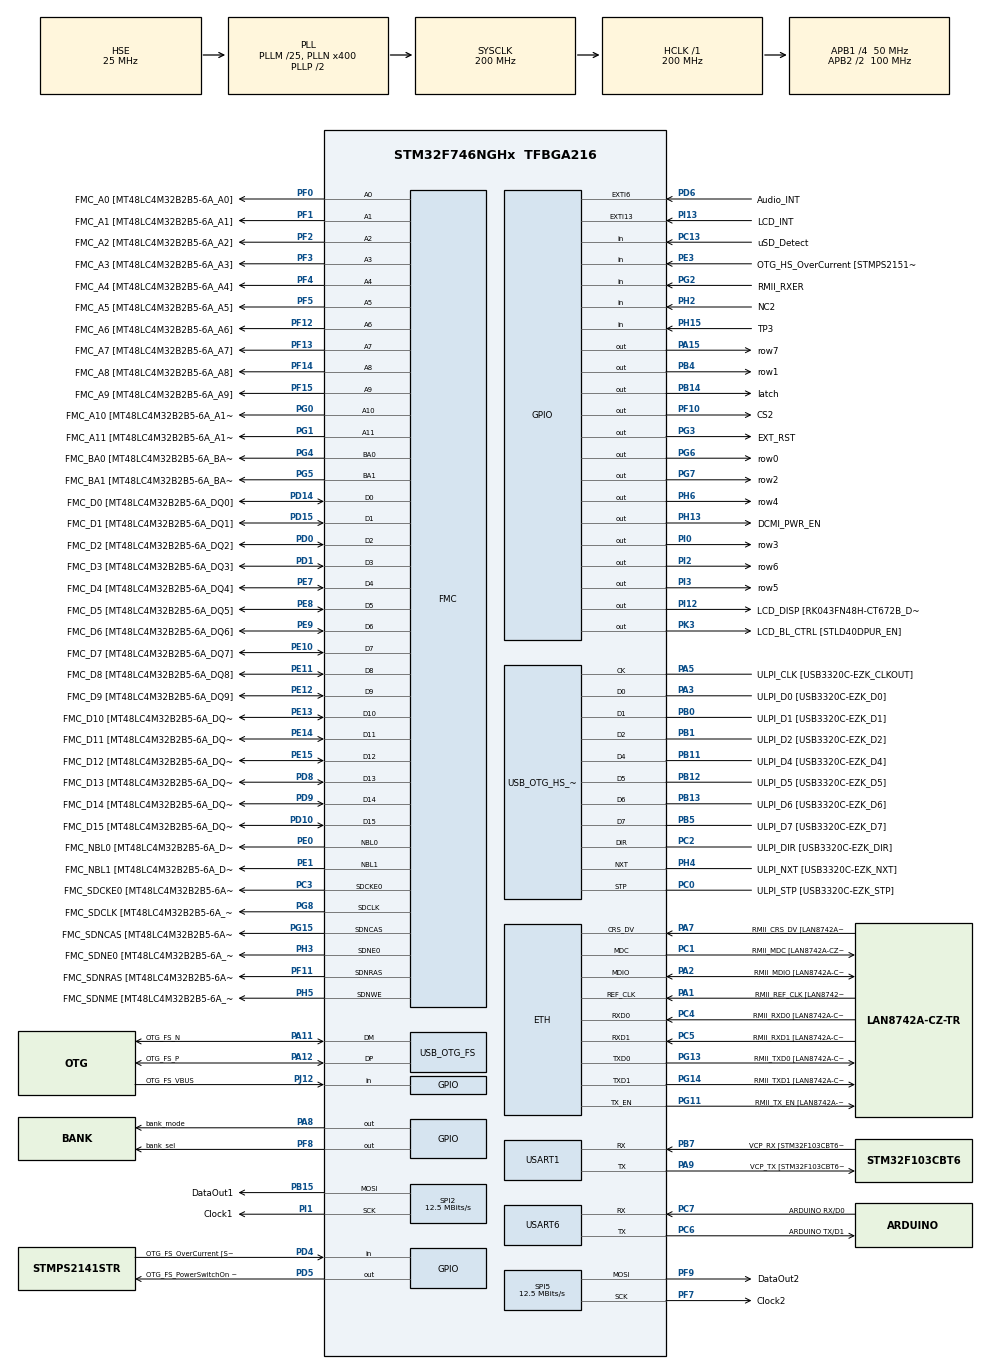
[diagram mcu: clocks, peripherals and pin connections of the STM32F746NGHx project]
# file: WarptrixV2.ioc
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Dma.MEMTOMEM.0.Direction=DMA_MEMORY_TO_MEMORY
Dma.MEMTOMEM.0.FIFOMode=DMA_FIFOMODE_ENABLE
Dma.MEMTOMEM.0.FIFOThreshold=DMA_FIFO_THRESHOLD_FULL
Dma.MEMTOMEM.0.Instance=DMA2_Stream4
Dma.MEMTOMEM.0.MemBurst=DMA_MBURST_SINGLE
Dma.MEMTOMEM.0.MemDataAlignment=DMA_MDATAALIGN_BYTE
Dma.MEMTOMEM.0.MemInc=DMA_MINC_ENABLE
Dma.MEMTOMEM.0.Mode=DMA_NORMAL
Dma.MEMTOMEM.0.PeriphBurst=DMA_PBURST_SINGLE
Dma.MEMTOMEM.0.PeriphDataAlignment=DMA_PDATAALIGN_BYTE
Dma.MEMTOMEM.0.PeriphInc=DMA_PINC_ENABLE
Dma.MEMTOMEM.0.Priority=DMA_PRIORITY_LOW
Dma.Request0=MEMTOMEM
Dma.Request1=SPI5_TX
Dma.Request2=SPI2_TX
Dma.SPI2_TX.2.Direction=DMA_MEMORY_TO_PERIPH
Dma.SPI2_TX.2.FIFOMode=DMA_FIFOMODE_DISABLE
Dma.SPI2_TX.2.Instance=DMA1_Stream4
Dma.SPI2_TX.2.MemDataAlignment=DMA_MDATAALIGN_BYTE
Dma.SPI2_TX.2.MemInc=DMA_MINC_ENABLE
Dma.SPI2_TX.2.Mode=DMA_NORMAL
Dma.SPI2_TX.2.PeriphDataAlignment=DMA_PDATAALIGN_BYTE
Dma.SPI2_TX.2.PeriphInc=DMA_PINC_DISABLE
Dma.SPI2_TX.2.Priority=DMA_PRIORITY_VERY_HIGH
Dma.SPI5_TX.1.Direction=DMA_MEMORY_TO_PERIPH
Dma.SPI5_TX.1.FIFOMode=DMA_FIFOMODE_DISABLE
Dma.SPI5_TX.1.Instance=DMA2_Stream6
Dma.SPI5_TX.1.MemDataAlignment=DMA_MDATAALIGN_BYTE
Dma.SPI5_TX.1.MemInc=DMA_MINC_ENABLE
Dma.SPI5_TX.1.Mode=DMA_NORMAL
Dma.SPI5_TX.1.PeriphDataAlignment=DMA_PDATAALIGN_BYTE
Dma.SPI5_TX.1.PeriphInc=DMA_PINC_DISABLE
Dma.SPI5_TX.1.Priority=DMA_PRIORITY_VERY_HIGH
ETH.MACAddr=00\:6D\:69\:6B\:75\:02
ETH.MediaInterface=ETH_MEDIA_INTERFACE_RMII
ETH.PHY_Name=LAN8742A_PHY_ADDRESS
ETH.PHY_RESET_DELAY=0x00000FFF
ETH.PhyAddress=0
FMC.CASLatency1=FMC_SDRAM_CAS_LATENCY_3
FMC.ExitSelfRefreshDelay1=7
FMC.LoadToActiveDelay1=2
FMC.RCDDelay1=2
FMC.RPDelay1=2
FMC.RPDelay2=2
FMC.ReadBurst1=FMC_SDRAM_RBURST_ENABLE
FMC.ReadBurst2=FMC_SDRAM_RBURST_ENABLE
FMC.RowCycleDelay1=7
FMC.RowCycleDelay2=7
FMC.SDClockPeriod1=FMC_SDRAM_CLOCK_PERIOD_2
FMC.SDClockPeriod2=FMC_SDRAM_CLOCK_PERIOD_2
FMC.SelfRefreshTime1=4
FMC.WriteRecoveryTime1=3
LWIP.LWIP_DISABLE_TCP_SANITY_CHECKS=0
LWIP.MEMP_NUM_TCP_PCB=5
LWIP.MEMP_NUM_UDP_PCB=1
LWIP.Version=v2.0.3_Cube
Mcu.Family=STM32F7
Mcu.Name=STM32F746NGHx
Mcu.Package=TFBGA216
NVIC.DMA1_Stream4_IRQn=true\:0\:0\:false\:false\:true\:false
NVIC.DMA2_Stream6_IRQn=true\:0\:0\:false\:false\:true\:false
NVIC.OTG_FS_IRQn=true\:0\:0\:false\:false\:true\:true
NVIC.PriorityGroup=NVIC_PRIORITYGROUP_4
NVIC.TIM1_BRK_TIM9_IRQn=true\:0\:0\:false\:false\:true\:true
NVIC.TIM6_DAC_IRQn=true\:0\:0\:false\:false\:true\:false
NVIC.TIM8_TRG_COM_TIM14_IRQn=true\:0\:0\:false\:false\:true\:true
NVIC.TimeBase=TIM6_DAC_IRQn
NVIC.TimeBaseIP=TIM6
PA0/WKUP.GPIO_Label=ARDUINO A0
PA0/WKUP.GPIO_Mode=GPIO_MODE_ANALOG
PA0/WKUP.GPIO_PuPd=GPIO_NOPULL
PA0/WKUP.Signal=ADCx_IN0
PA1.GPIO_Label=RMII_REF_CLK [LAN8742A-CZ-TR_REFCLK0]
PA1.Mode=RMII
PA1.Signal=ETH_REF_CLK
PA10.GPIO_Label=OTG_FS_ID
PA10.Signal=USB_OTG_FS_ID
PA11.GPIO_Label=OTG_FS_N
PA11.Mode=Device_Only
PA11.Signal=USB_OTG_FS_DM
PA12.GPIO_Label=OTG_FS_P
PA12.Mode=Device_Only
PA12.Signal=USB_OTG_FS_DP
PA13.GPIO_Label=SWDIO
PA13.Mode=Serial_Wire
PA13.Signal=SYS_JTMS-SWDIO
PA14.GPIO_Label=SWCLK
PA14.Mode=Serial_Wire
PA14.Signal=SYS_JTCK-SWCLK
PA15.GPIO_Label=row7
PA15.Signal=GPIO_Output
PA2.GPIO_Label=RMII_MDIO [LAN8742A-CZ-TR_MDIO]
PA2.Mode=RMII
PA2.Signal=ETH_MDIO
PA3.GPIO_Label=ULPI_D0 [USB3320C-EZK_D0]
PA3.Mode=Host_HS
PA3.Signal=USB_OTG_HS_ULPI_D0
PA4.GPIO_Label=DCMI_HSYNC
PA4.Signal=DCMI_HSYNC
PA5.GPIO_Label=ULPI_CLK [USB3320C-EZK_CLKOUT]
PA5.Mode=Host_HS
PA5.Signal=USB_OTG_HS_ULPI_CK
PA6.Signal=DCMI_PIXCLK
PA7.GPIO_Label=RMII_CRS_DV [LAN8742A-CZ-TR_CRS_DV]
PA7.Mode=RMII
PA7.Signal=ETH_CRS_DV
PA8.GPIO_Label=bank_mode
PA8.PinState=GPIO_PIN_SET
PA8.Signal=GPIO_Output
PA9.GPIO_Label=VCP_TX [STM32F103CBT6_PA3]
PA9.GPIO_Mode=GPIO_MODE_AF_PP
PA9.GPIO_PuPd=GPIO_NOPULL
PA9.GPIO_Speed=GPIO_SPEED_FREQ_LOW
PA9.Mode=Asynchronous
PA9.Signal=USART1_TX
PB0.GPIO_Label=ULPI_D1 [USB3320C-EZK_D1]
PB0.Mode=Host_HS
PB0.Signal=USB_OTG_HS_ULPI_D1
PB1.GPIO_Label=ULPI_D2 [USB3320C-EZK_D2]
PB1.Mode=Host_HS
PB1.Signal=USB_OTG_HS_ULPI_D2
PB10.GPIO_Label=ULPI_D3 [USB3320C-EZK_D3]
PB10.Signal=USB_OTG_HS_ULPI_D3
PB11.GPIO_Label=ULPI_D4 [USB3320C-EZK_D4]
PB11.Mode=Host_HS
PB11.Signal=USB_OTG_HS_ULPI_D4
PB12.GPIO_Label=ULPI_D5 [USB3320C-EZK_D5]
PB12.Mode=Host_HS
PB12.Signal=USB_OTG_HS_ULPI_D5
PB13.GPIO_Label=ULPI_D6 [USB3320C-EZK_D6]
PB13.Mode=Host_HS
PB13.Signal=USB_OTG_HS_ULPI_D6
PB14.GPIO_Label=latch
PB14.Signal=GPIO_Output
PB15.GPIO_Label=DataOut1
PB15.GPIO_Mode=GPIO_MODE_AF_PP
PB15.GPIO_PuPd=GPIO_NOPULL
PB15.GPIO_Speed=GPIO_SPEED_FREQ_VERY_HIGH
PB15.Mode=TX_Only_Simplex_Unidirect_Master
PB15.Signal=SPI2_MOSI
PB2.Signal=QUADSPI_CLK
PB3.GPIO_Label=SWO
PB3.Signal=SYS_JTDO-SWO
PB4.GPIO_Label=row1
PB4.Signal=GPIO_Output
PB5.GPIO_Label=ULPI_D7 [USB3320C-EZK_D7]
PB5.Mode=Host_HS
PB5.Signal=USB_OTG_HS_ULPI_D7
PB6.GPIO_Label=QSPI_NCS [N25Q128A13EF840E_S]
PB6.Signal=QUADSPI_BK1_NCS
PB7.GPIO_Label=VCP_RX [STM32F103CBT6_PA2]
PB7.GPIO_Mode=GPIO_MODE_AF_PP
PB7.GPIO_PuPd=GPIO_NOPULL
PB7.GPIO_Speed=GPIO_SPEED_FREQ_LOW
PB7.Mode=Asynchronous
PB7.Signal=USART1_RX
PB8.GPIO_Label=ARDUINO SCL/D15
PB8.GPIO_Mode=GPIO_MODE_AF_OD
PB8.GPIO_PuPd=GPIO_NOPULL
PB8.GPIO_Speed=GPIO_SPEED_FREQ_LOW
PB8.Signal=I2C1_SCL
PB9.GPIO_Label=ARDUINO SDA/D14
PB9.GPIO_Mode=GPIO_MODE_AF_OD
PB9.GPIO_PuPd=GPIO_NOPULL
PB9.GPIO_Speed=GPIO_SPEED_FREQ_LOW
PB9.Signal=I2C1_SDA
PC0.GPIO_Label=ULPI_STP [USB3320C-EZK_STP]
PC0.Mode=Host_HS
PC0.Signal=USB_OTG_HS_ULPI_STP
PC1.GPIO_Label=RMII_MDC [LAN8742A-CZ-TR_MDC]
PC1.Mode=RMII
PC1.Signal=ETH_MDC
PC10.GPIO_Label=SDMMC_D2
PC10.Signal=SDMMC1_D2
PC11.GPIO_Label=SDMMC_D3
PC11.Signal=SDMMC1_D3
PC12.GPIO_Label=SDMMC_CK
PC12.Signal=SDMMC1_CK
PC13.GPIO_Label=uSD_Detect
PC13.Signal=GPIO_Input
PC14/OSC32_IN.GPIO_Label=RCC_OSC32_IN
PC14/OSC32_IN.Mode=LSE-External-Oscillator
PC14/OSC32_IN.Signal=RCC_OSC32_IN
PC15/OSC32_OUT.GPIO_Label=RCC_OSC32_OUT
PC15/OSC32_OUT.Mode=LSE-External-Oscillator
PC15/OSC32_OUT.Signal=RCC_OSC32_OUT
PC2.GPIO_Label=ULPI_DIR [USB3320C-EZK_DIR]
PC2.Mode=Host_HS
PC2.Signal=USB_OTG_HS_ULPI_DIR
PC3.GPIO_Label=FMC_SDCKE0 [MT48LC4M32B2B5-6A_CKE]
PC3.Mode=SdramChipSelect1_1
PC3.Signal=FMC_SDCKE0
PC4.GPIO_Label=RMII_RXD0 [LAN8742A-CZ-TR_RXD0]
PC4.Mode=RMII
PC4.Signal=ETH_RXD0
PC5.GPIO_Label=RMII_RXD1 [LAN8742A-CZ-TR_RXD1]
PC5.Mode=RMII
PC5.Signal=ETH_RXD1
PC6.GPIO_Label=ARDUINO TX/D1
PC6.Mode=Asynchronous
PC6.Signal=USART6_TX
PC7.GPIO_Label=ARDUINO RX/D0
PC7.Mode=Asynchronous
PC7.Signal=USART6_RX
PC8.Signal=SDMMC1_D0
PC9.Signal=SDMMC1_D1
PD0.GPIO_Label=FMC_D2 [MT48LC4M32B2B5-6A_DQ2]
PD0.Signal=FMC_D2_DA2
PD1.GPIO_Label=FMC_D3 [MT48LC4M32B2B5-6A_DQ3]
PD1.Signal=FMC_D3_DA3
PD10.GPIO_Label=FMC_D15 [MT48LC4M32B2B5-6A_DQ15]
PD10.Signal=FMC_D15_DA15
PD11.GPIO_Label=QSPI_D0 [N25Q128A13EF840E_DQ0]
PD11.Signal=QUADSPI_BK1_IO0
PD12.GPIO_Label=QSPI_D1 [N25Q128A13EF840E_DQ1]
PD12.Signal=QUADSPI_BK1_IO1
PD13.GPIO_Label=QSPI_D3 [N25Q128A13EF840E_DQ3]
PD13.Signal=QUADSPI_BK1_IO3
PD14.GPIO_Label=FMC_D0 [MT48LC4M32B2B5-6A_DQ0]
PD14.Signal=FMC_D0_DA0
PD15.GPIO_Label=FMC_D1 [MT48LC4M32B2B5-6A_DQ1]
PD15.Signal=FMC_D1_DA1
PD2.GPIO_Label=SDMMC_CMD
PD2.Signal=SDMMC1_CMD
PD3.GPIO_Label=DCMI_D5
PD3.Signal=DCMI_D5
PD4.GPIO_Label=OTG_FS_OverCurrent [STMPS2141STR_Fault]
PD4.Signal=GPIO_Input
PD5.GPIO_Label=OTG_FS_PowerSwitchOn [STMPS2141STR_EN]
PD5.PinState=GPIO_PIN_SET
PD5.Signal=GPIO_Output
PD6.GPIO_Label=Audio_INT
PD6.GPIO_ModeDefaultEXTI=GPIO_MODE_EVT_RISING
PD6.Signal=GPXTI6
PD7.GPIO_Label=SPDIF_RX0 [74LVC1G04SE_4]
PD7.Signal=SPDIFRX_IN0
PD8.GPIO_Label=FMC_D13 [MT48LC4M32B2B5-6A_DQ13]
PD8.Signal=FMC_D13_DA13
PD9.GPIO_Label=FMC_D14 [MT48LC4M32B2B5-6A_DQ14]
PD9.Signal=FMC_D14_DA14
PE0.GPIO_Label=FMC_NBL0 [MT48LC4M32B2B5-6A_DQM0]
PE0.Signal=FMC_NBL0
PE1.GPIO_Label=FMC_NBL1 [MT48LC4M32B2B5-6A_DQM1]
PE1.Signal=FMC_NBL1
PE10.GPIO_Label=FMC_D7 [MT48LC4M32B2B5-6A_DQ7]
PE10.Signal=FMC_D7_DA7
PE11.GPIO_Label=FMC_D8 [MT48LC4M32B2B5-6A_DQ8]
PE11.Signal=FMC_D8_DA8
PE12.GPIO_Label=FMC_D9 [MT48LC4M32B2B5-6A_DQ9]
PE12.Signal=FMC_D9_DA9
PE13.GPIO_Label=FMC_D10 [MT48LC4M32B2B5-6A_DQ10]
PE13.Signal=FMC_D10_DA10
PE14.GPIO_Label=FMC_D11 [MT48LC4M32B2B5-6A_DQ11]
PE14.Signal=FMC_D11_DA11
PE15.GPIO_Label=FMC_D12 [MT48LC4M32B2B5-6A_DQ12]
PE15.Signal=FMC_D12_DA12
PE2.GPIO_Label=QSPI_D2 [N25Q128A13EF840E_DQ2]
PE2.Signal=QUADSPI_BK1_IO2
PE3.GPIO_Label=OTG_HS_OverCurrent [STMPS2151STR_FAULT]
PE3.Signal=GPIO_Input
PE4.GPIO_Label=LCD_B0 [RK043FN48H-CT672B_B0]
PE4.Signal=LTDC_B0
PE5.GPIO_Label=DCMI_D6
PE5.Signal=DCMI_D6
PE6.GPIO_Label=DCMI_D7
PE6.Signal=DCMI_D7
PE7.GPIO_Label=FMC_D4 [MT48LC4M32B2B5-6A_DQ4]
PE7.Signal=FMC_D4_DA4
PE8.GPIO_Label=FMC_D5 [MT48LC4M32B2B5-6A_DQ5]
PE8.Signal=FMC_D5_DA5
PE9.GPIO_Label=FMC_D6 [MT48LC4M32B2B5-6A_DQ6]
PE9.Signal=FMC_D6_DA6
PF0.GPIO_Label=FMC_A0 [MT48LC4M32B2B5-6A_A0]
PF0.Signal=FMC_A0
PF1.GPIO_Label=FMC_A1 [MT48LC4M32B2B5-6A_A1]
PF1.Signal=FMC_A1
PF10.GPIO_Label=CS2
PF10.Signal=GPIO_Output
PF11.GPIO_Label=FMC_SDNRAS [MT48LC4M32B2B5-6A_RAS]
PF11.Signal=FMC_SDNRAS
PF12.GPIO_Label=FMC_A6 [MT48LC4M32B2B5-6A_A6]
PF12.Signal=FMC_A6
PF13.GPIO_Label=FMC_A7 [MT48LC4M32B2B5-6A_A7]
PF13.Signal=FMC_A7
PF14.GPIO_Label=FMC_A8 [MT48LC4M32B2B5-6A_A8]
PF14.Signal=FMC_A8
PF15.GPIO_Label=FMC_A9 [MT48LC4M32B2B5-6A_A9]
PF15.Signal=FMC_A9
PF2.GPIO_Label=FMC_A2 [MT48LC4M32B2B5-6A_A2]
PF2.Signal=FMC_A2
PF3.GPIO_Label=FMC_A3 [MT48LC4M32B2B5-6A_A3]
PF3.Signal=FMC_A3
PF4.GPIO_Label=FMC_A4 [MT48LC4M32B2B5-6A_A4]
PF4.Signal=FMC_A4
PF5.GPIO_Label=FMC_A5 [MT48LC4M32B2B5-6A_A5]
PF5.Signal=FMC_A5
PF6.GPIO_Label=ARDUINO A5
PF6.GPIO_Mode=GPIO_MODE_ANALOG
PF6.GPIO_PuPd=GPIO_NOPULL
PF6.Signal=ADC3_IN4
PF7.GPIO_Label=Clock2
PF7.Mode=TX_Only_Simplex_Unidirect_Master
PF7.Signal=SPI5_SCK
PF8.GPIO_Label=bank_sel
PF8.Signal=GPIO_Output
PF9.GPIO_Label=DataOut2
PF9.Mode=TX_Only_Simplex_Unidirect_Master
PF9.Signal=SPI5_MOSI
PG0.GPIO_Label=FMC_A10 [MT48LC4M32B2B5-6A_A10]
PG0.Signal=FMC_A10
PG1.GPIO_Label=FMC_A11 [MT48LC4M32B2B5-6A_A11]
PG1.Signal=FMC_A11
PG10.GPIO_Label=SAI2_SDB [WM8994ECS/R_ADCDAT1]
PG10.Signal=SAI2_SD_B
PG11.GPIO_Label=RMII_TX_EN [LAN8742A-CZ-TR_TXEN]
PG11.Mode=RMII
PG11.Signal=ETH_TX_EN
PG12.GPIO_Label=LCD_B4 [RK043FN48H-CT672B_B4]
PG12.Signal=LTDC_B4
PG13.GPIO_Label=RMII_TXD0 [LAN8742A-CZ-TR_TXD0]
PG13.Mode=RMII
PG13.Signal=ETH_TXD0
PG14.GPIO_Label=RMII_TXD1 [LAN8742A-CZ-TR_TXD1]
PG14.Mode=RMII
PG14.Signal=ETH_TXD1
PG15.GPIO_Label=FMC_SDNCAS [MT48LC4M32B2B5-6A_CAS]
PG15.Signal=FMC_SDNCAS
PG2.GPIO_Label=RMII_RXER
PG2.Signal=GPIO_Input
PG3.GPIO_Label=EXT_RST
PG3.Signal=GPIO_Output
PG4.GPIO_Label=FMC_BA0 [MT48LC4M32B2B5-6A_BA0]
PG4.Signal=FMC_A14_BA0
PG5.GPIO_Label=FMC_BA1 [MT48LC4M32B2B5-6A_BA1]
PG5.Signal=FMC_A15_BA1
PG6.GPIO_Label=row0
PG6.Signal=GPIO_Output
PG7.GPIO_Label=row2
PG7.Signal=GPIO_Output
PG8.GPIO_Label=FMC_SDCLK [MT48LC4M32B2B5-6A_CLK]
PG8.Signal=FMC_SDCLK
PG9.GPIO_Label=DCMI_VSYNC
PG9.Signal=DCMI_VSYNC
PH0/OSC_IN.GPIO_Label=OSC_25M [NZ2520SB-25.00M_OUT]
PH0/OSC_IN.Mode=HSE-External-Oscillator
PH0/OSC_IN.Signal=RCC_OSC_IN
PH1/OSC_OUT.Mode=HSE-External-Oscillator
PH1/OSC_OUT.Signal=RCC_OSC_OUT
PH10.GPIO_Label=DCMI_D1
PH10.Signal=DCMI_D1
PH11.GPIO_Label=DCMI_D2
PH11.Signal=DCMI_D2
PH12.GPIO_Label=DCMI_D3
PH12.Signal=DCMI_D3
PH13.GPIO_Label=DCMI_PWR_EN
PH13.Signal=GPIO_Output
PH14.GPIO_Label=DCMI_D4
PH14.Signal=DCMI_D4
PH15.GPIO_Label=TP3
PH15.Signal=GPIO_Input
PH2.GPIO_Label=NC2
PH2.Signal=GPIO_Input
PH3.GPIO_Label=FMC_SDNE0 [MT48LC4M32B2B5-6A_CS]
PH3.Mode=SdramChipSelect1_1
PH3.Signal=FMC_SDNE0
PH4.GPIO_Label=ULPI_NXT [USB3320C-EZK_NXT]
PH4.Mode=Host_HS
PH4.Signal=USB_OTG_HS_ULPI_NXT
PH5.GPIO_Label=FMC_SDNME [MT48LC4M32B2B5-6A_WE]
PH5.Signal=FMC_SDNWE
PH6.GPIO_Label=row4
PH6.Signal=GPIO_Output
PH7.GPIO_Label=LCD_SCL [RK043FN48H-CT672B_SCL]
PH7.Signal=I2C3_SCL
PH8.GPIO_Label=LCD_SDA [RK043FN48H-CT672B_SDA]
PH8.Signal=I2C3_SDA
PH9.GPIO_Label=DCMI_D0
PH9.Signal=DCMI_D0
PI0.GPIO_Label=row3
PI0.Signal=GPIO_Output
PI1.GPIO_Label=Clock1
PI1.GPIO_Mode=GPIO_MODE_AF_PP
PI1.GPIO_PuPd=GPIO_NOPULL
PI1.GPIO_Speed=GPIO_SPEED_FREQ_VERY_HIGH
PI1.Mode=TX_Only_Simplex_Unidirect_Master
PI1.Signal=SPI2_SCK
PI10.GPIO_Label=LCD_HSYNC [RK043FN48H-CT672B_HSYNC]
PI10.Signal=LTDC_HSYNC
PI12.GPIO_Label=LCD_DISP [RK043FN48H-CT672B_DISP] 
PI12.PinState=GPIO_PIN_SET
PI12.Signal=GPIO_Output
PI13.GPIO_Label=LCD_INT
PI13.GPIO_ModeDefaultEXTI=GPIO_MODE_EVT_RISING
PI13.Signal=GPXTI13
PI14.GPIO_Label=LCD_CLK [RK043FN48H-CT672B_CLK]
PI14.Signal=LTDC_CLK
PI15.GPIO_Label=LCD_R0 [RK043FN48H-CT672B_R0]
PI15.Signal=LTDC_R0
PI2.GPIO_Label=row6
PI2.Signal=GPIO_Output
PI3.GPIO_Label=row5
PI3.Signal=GPIO_Output
PI4.GPIO_Label=SAI2_MCLKA [WM8994ECS/R_MCLK1]
PI4.Signal=SAI2_MCLK_A
PI5.GPIO_Label=SAI2_SCKA [WM8994ECS/R_BCLK1]
PI5.Signal=SAI2_SCK_A
PI6.GPIO_Label=SAI2_SDA [WM8994ECS/R_DACDAT1]
PI6.Signal=SAI2_SD_A
PI7.GPIO_Label=SAI2_FSA [WM8994ECS/R_LRCLK1]
PI7.Signal=SAI2_FS_A
PI8.GPIO_Label=NC1 [TP2]
PI8.Signal=RTC_TS
PI9.GPIO_Label=LCD_VSYNC [RK043FN48H-CT672B_VSYNC]
PI9.Signal=LTDC_VSYNC
PJ0.GPIO_Label=LCD_R1 [RK043FN48H-CT672B_R1]
PJ0.Signal=LTDC_R1
PJ1.GPIO_Label=LCD_R2 [RK043FN48H-CT672B_R2]
PJ1.Signal=LTDC_R2
PJ10.GPIO_Label=LCD_G3 [RK043FN48H-CT672B_G3]
PJ10.Signal=LTDC_G3
PJ11.GPIO_Label=LCD_G4 [RK043FN48H-CT672B_G4]
PJ11.Signal=LTDC_G4
PJ12.GPIO_Label=OTG_FS_VBUS
PJ12.Signal=GPIO_Input
PJ13.GPIO_Label=LCD_B1 [RK043FN48H-CT672B_B1]
PJ13.Signal=LTDC_B1
PJ14.GPIO_Label=LCD_B2 [RK043FN48H-CT672B_B2]
PJ14.Signal=LTDC_B2
PJ15.GPIO_Label=LCD_B3 [RK043FN48H-CT672B_B3]
PJ15.Signal=LTDC_B3
PJ2.GPIO_Label=LCD_R3 [RK043FN48H-CT672B_R3]
PJ2.Signal=LTDC_R3
PJ3.GPIO_Label=LCD_R4 [RK043FN48H-CT672B_R4]
PJ3.Signal=LTDC_R4
PJ4.GPIO_Label=LCD_R5 [RK043FN48H-CT672B_R5]
PJ4.Signal=LTDC_R5
PJ5.GPIO_Label=LCD_R6 [RK043FN48H-CT672B_R6]
PJ5.Signal=LTDC_R6
PJ6.GPIO_Label=LCD_R7 [RK043FN48H-CT672B_R7]
PJ6.Signal=LTDC_R7
PJ7.GPIO_Label=LCD_G0 [RK043FN48H-CT672B_G0]
PJ7.Signal=LTDC_G0
PJ8.GPIO_Label=LCD_G1 [RK043FN48H-CT672B_G1]
PJ8.Signal=LTDC_G1
PJ9.GPIO_Label=LCD_G2 [RK043FN48H-CT672B_G2]
PJ9.Signal=LTDC_G2
PK0.GPIO_Label=LCD_G5 [RK043FN48H-CT672B_G5]
PK0.Signal=LTDC_G5
PK1.GPIO_Label=LCD_G6 [RK043FN48H-CT672B_G6]
PK1.Signal=LTDC_G6
PK2.GPIO_Label=LCD_G7 [RK043FN48H-CT672B_G7]
PK2.Signal=LTDC_G7
PK3.GPIO_Label=LCD_BL_CTRL [STLD40DPUR_EN]
PK3.GPIO_Speed=GPIO_SPEED_FREQ_LOW
PK3.PinState=GPIO_PIN_SET
PK3.Signal=GPIO_Output
PK4.GPIO_Label=LCD_B5 [RK043FN48H-CT672B_B5]
PK4.Signal=LTDC_B5
PK5.GPIO_Label=LCD_B6 [RK043FN48H-CT672B_B6]
PK5.Signal=LTDC_B6
PK6.GPIO_Label=LCD_B7 [RK043FN48H-CT672B_B7]
PK6.Signal=LTDC_B7
PK7.GPIO_Label=LCD_DE [RK043FN48H-CT672B_DE]
PK7.Signal=LTDC_DE
ProjectManager.HeapSize=0x200
ProjectManager.StackSize=0x400
ProjectManager.TargetToolchain=Makefile
RCC.AHBFreq_Value=200000000
RCC.APB1CLKDivider=RCC_HCLK_DIV4
RCC.APB1Freq_Value=50000000
RCC.APB1TimFreq_Value=100000000
RCC.APB2CLKDivider=RCC_HCLK_DIV2
RCC.APB2Freq_Value=100000000
RCC.APB2TimFreq_Value=200000000
RCC.CortexFreq_Value=200000000
RCC.HCLKFreq_Value=200000000
RCC.HSE_VALUE=25000000
RCC.HSI_VALUE=16000000
RCC.PLL48CLockSelection=RCC_CLK48SOURCE_PLLSAIP
RCC.PLLI2SN=100
RCC.PLLM=25
RCC.PLLN=400
RCC.PLLQ=9
RCC.PLLSAIN=384
RCC.PLLSAIP=RCC_PLLSAIP_DIV8
RCC.PLLSAIR=5
RCC.PLLSAIRDiv=RCC_PLLSAIDIVR_8
RCC.SDMMCClockSelection=RCC_SDMMC1CLKSOURCE_CLK48
RCC.SYSCLKFreq_VALUE=200000000
RCC.SYSCLKSource=RCC_SYSCLKSOURCE_PLLCLK
RCC.USBFreq_Value=48000000
RCC.VCOOutputFreq_Value=400000000
SH.ADCx_IN0.0=ADC3_IN0
SH.FMC_A0.0=FMC_A0,12b-sda1
SH.FMC_A1.0=FMC_A1,12b-sda1
SH.FMC_A10.0=FMC_A10,12b-sda1
SH.FMC_A11.0=FMC_A11,12b-sda1
SH.FMC_A14_BA0.0=FMC_BA0,FourSdramBanks1
SH.FMC_A15_BA1.0=FMC_BA1,FourSdramBanks1
SH.FMC_A2.0=FMC_A2,12b-sda1
SH.FMC_A3.0=FMC_A3,12b-sda1
SH.FMC_A4.0=FMC_A4,12b-sda1
SH.FMC_A5.0=FMC_A5,12b-sda1
SH.FMC_A6.0=FMC_A6,12b-sda1
SH.FMC_A7.0=FMC_A7,12b-sda1
SH.FMC_A8.0=FMC_A8,12b-sda1
SH.FMC_A9.0=FMC_A9,12b-sda1
SH.FMC_D0_DA0.0=FMC_D0,sd-16b-d1
SH.FMC_D10_DA10.0=FMC_D10,sd-16b-d1
SH.FMC_D11_DA11.0=FMC_D11,sd-16b-d1
SH.FMC_D12_DA12.0=FMC_D12,sd-16b-d1
SH.FMC_D13_DA13.0=FMC_D13,sd-16b-d1
SH.FMC_D14_DA14.0=FMC_D14,sd-16b-d1
SH.FMC_D15_DA15.0=FMC_D15,sd-16b-d1
SH.FMC_D1_DA1.0=FMC_D1,sd-16b-d1
SH.FMC_D2_DA2.0=FMC_D2,sd-16b-d1
SH.FMC_D3_DA3.0=FMC_D3,sd-16b-d1
SH.FMC_D4_DA4.0=FMC_D4,sd-16b-d1
SH.FMC_D5_DA5.0=FMC_D5,sd-16b-d1
SH.FMC_D6_DA6.0=FMC_D6,sd-16b-d1
SH.FMC_D7_DA7.0=FMC_D7,sd-16b-d1
SH.FMC_D8_DA8.0=FMC_D8,sd-16b-d1
SH.FMC_D9_DA9.0=FMC_D9,sd-16b-d1
SH.FMC_NBL0.0=FMC_NBL0,Sd2ByteEnable1
SH.FMC_NBL1.0=FMC_NBL1,Sd2ByteEnable1
SH.FMC_SDCLK.0=FMC_SDCLK,12b-sda1
SH.FMC_SDNCAS.0=FMC_SDNCAS,12b-sda1
SH.FMC_SDNRAS.0=FMC_SDNRAS,12b-sda1
SH.FMC_SDNWE.0=FMC_SDNWE,12b-sda1
SPI2.BaudRatePrescaler=SPI_BAUDRATEPRESCALER_4
SPI2.CLKPhase=SPI_PHASE_2EDGE
SPI2.CalculateBaudRate=12.5 MBits/s
SPI2.DataSize=SPI_DATASIZE_8BIT
SPI2.Direction=SPI_DIRECTION_2LINES
SPI2.FirstBit=SPI_FIRSTBIT_LSB
SPI2.Mode=SPI_MODE_MASTER
SPI2.VirtualType=VM_MASTER
SPI5.BaudRatePrescaler=SPI_BAUDRATEPRESCALER_8
SPI5.CLKPhase=SPI_PHASE_2EDGE
SPI5.CLKPolarity=SPI_POLARITY_HIGH
SPI5.CalculateBaudRate=12.5 MBits/s
SPI5.DataSize=SPI_DATASIZE_8BIT
SPI5.Direction=SPI_DIRECTION_2LINES
SPI5.FirstBit=SPI_FIRSTBIT_LSB
SPI5.Mode=SPI_MODE_MASTER
SPI5.VirtualType=VM_MASTER
TIM9.Period=5000
TIM9.Prescaler=2
USART1.VirtualMode-Asynchronous=VM_ASYNC
USART6.VirtualMode-Asynchronous=VM_ASYNC
USB_DEVICE.CLASS_NAME_FS=CDC
USB_DEVICE.LANGID_STRING-CDC_FS=1031
USB_DEVICE.MANUFACTURER_STRING-CDC_FS=Warpzone
USB_DEVICE.PID_CDC_FS=14649
USB_DEVICE.USBD_DEBUG_LEVEL-CDC_FS=2
USB_DEVICE.USBD_SELF_POWERED-CDC_FS=1
USB_DEVICE.VID-CDC_FS=4919
USB_DEVICE.VirtualMode-CDC_FS=Cdc
USB_DEVICE.VirtualModeFS=Cdc_FS
USB_OTG_FS.VirtualMode=Device_Only
VP_CRC_VS_CRC.Mode=CRC_Activate
VP_LWIP_VS_Enabled.Mode=Enabled
VP_SYS_VS_tim6.Mode=TIM6
VP_TIM1_VS_ClockSourceINT.Mode=Internal
VP_TIM2_VS_ClockSourceINT.Mode=Internal
VP_TIM3_VS_ClockSourceINT.Mode=Internal
VP_TIM5_VS_ClockSourceINT.Mode=Internal
VP_TIM8_VS_ClockSourceINT.Mode=Internal
VP_TIM9_VS_ClockSourceINT.Mode=Internal
VP_USB_DEVICE_VS_USB_DEVICE_CDC_FS.Mode=CDC_FS
board=32F746GDISCOVERY

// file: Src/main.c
/**
  ******************************************************************************
  * @file           : main.c
  * @brief          : Main program body
  ******************************************************************************
  * This notice applies to any and all portions of this file
  * that are not between comment pairs USER CODE BEGIN and
  * USER CODE END. Other portions of this file, whether
  * inserted by the user or by software development tools
  * are owned by their respective copyright owners.
  *
  * Copyright (c) 2019 STMicroelectronics International N.V.
  * All rights reserved.
  *
  * Redistribution and use in source and binary forms, with or without
  * modification, are permitted, provided that the following conditions are met:
  *
  * 1. Redistribution of source code must retain the above copyright notice,
  *    this list of conditions and the following disclaimer.
  * 2. Redistributions in binary form must reproduce the above copyright notice,
  *    this list of conditions and the following disclaimer in the documentation
  *    and/or other materials provided with the distribution.
  * 3. Neither the name of STMicroelectronics nor the names of other
  *    contributors to this software may be used to endorse or promote products
  *    derived from this software without specific written permission.
  * 4. This software, including modifications and/or derivative works of this
  *    software, must execute solely and exclusively on microcontroller or
  *    microprocessor devices manufactured by or for STMicroelectronics.
  * 5. Redistribution and use of this software other than as permitted under
  *    this license is void and will automatically terminate your rights under
  *    this license.
  *
  * THIS SOFTWARE IS PROVIDED BY STMICROELECTRONICS AND CONTRIBUTORS "AS IS"
  * AND ANY EXPRESS, IMPLIED OR STATUTORY WARRANTIES, INCLUDING, BUT NOT
  * LIMITED TO, THE IMPLIED WARRANTIES OF MERCHANTABILITY, FITNESS FOR A
  * PARTICULAR PURPOSE AND NON-INFRINGEMENT OF THIRD PARTY INTELLECTUAL PROPERTY
  * RIGHTS ARE DISCLAIMED TO THE FULLEST EXTENT PERMITTED BY LAW. IN NO EVENT
  * SHALL STMICROELECTRONICS OR CONTRIBUTORS BE LIABLE FOR ANY DIRECT, INDIRECT,
  * INCIDENTAL, SPECIAL, EXEMPLARY, OR CONSEQUENTIAL DAMAGES (INCLUDING, BUT NOT
  * LIMITED TO, PROCUREMENT OF SUBSTITUTE GOODS OR SERVICES; LOSS OF USE, DATA,
  * OR PROFITS; OR BUSINESS INTERRUPTION) HOWEVER CAUSED AND ON ANY THEORY OF
  * LIABILITY, WHETHER IN CONTRACT, STRICT LIABILITY, OR TORT (INCLUDING
  * NEGLIGENCE OR OTHERWISE) ARISING IN ANY WAY OUT OF THE USE OF THIS SOFTWARE,
  * EVEN IF ADVISED OF THE POSSIBILITY OF SUCH DAMAGE.
  *
  ******************************************************************************
  */
#include "main.h"
#include "stm32f7xx_hal.h"
#include "lwip.h"
#include "usb_device.h"

/* USER CODE BEGIN Includes */
#include "usbd_cdc_if.h"
#include "tcp.h"

/* USER CODE END Includes */

CRC_HandleTypeDef hcrc;

SPI_HandleTypeDef hspi2;
SPI_HandleTypeDef hspi5;
DMA_HandleTypeDef hdma_spi2_tx;
DMA_HandleTypeDef hdma_spi5_tx;

TIM_HandleTypeDef htim1;
TIM_HandleTypeDef htim2;
TIM_HandleTypeDef htim3;
TIM_HandleTypeDef htim5;
TIM_HandleTypeDef htim8;
TIM_HandleTypeDef htim9;

UART_HandleTypeDef huart1;
UART_HandleTypeDef huart6;

DMA_HandleTypeDef hdma_memtomem_dma2_stream4;
SDRAM_HandleTypeDef hsdram1;

/* USER CODE BEGIN PV */
/* Private variables ---------------------------------------------------------*/

#define PORT_TCP_RECEIVE 1236
#define TCP_CONNECTION_TIMEOUT 10

#define USB_MAP_DEBUGG 0
#define USB_SPI_DEBUGG 0
#define USB_TCP_DEBUGG 0
#define USB_TIM_DEBUGG 0
#define USB_NET_STATUS 0
#define USB_PBUF_DEBUGG 0
#define USB_WELCOME_MSG 0

#define VERSION_STRING "V0.1"
#define WELCOME_MSG "\r\n\r\nWarptrix LED-Panel on duty! \r\nWarptrix COMPORT debugg interface. \r\nVersion: '%s' \r\n\r\n"

#define SHIFTREGS_PER_PANEL 6 // Number of 8-bit shift registers per panel. Each register controlls 8 colums of the matrix
#define ROWS 8 // Number of row drivers. 1:8 row plexed matrix
#define X_PANEL_NR 10 // Nubmer of panels in X
#define Y_PANEL_NR 4 // Number of panels in Y.
#define SHIFTREGS (X_PANEL_NR*Y_PANEL_NR*SHIFTREGS_PER_PANEL) // Total number of registers (240 with 4 panels in Y, 120 with 2 in Y)
#define LATCH_DELAY 40 // number of NOPs to wait after the data is latched. Prevents ghosting between frames.
#define X_SIZE (X_PANEL_NR * SHIFTREGS_PER_PANEL * 4 / 3) //Number of registers (bytes) in X-direction 80.
#define Y_SIZE (Y_PANEL_NR * ROWS * 3)                //Number of LED rows, NOT bytes! 96
#define COLUMS (SHIFTREGS * 4) // 960
#define COLUMS_PER_PANEL (SHIFTREGS_PER_PANEL * 4)  // 24
#define SUBFRAMES 16// Max Number of Subframes. 4-bit SoftPWM for each LED

// State-machiene defines
#define STATE_NONE 0
// start command
#define STATE_S 1
#define STATE_ST 2
#define STATE_STA 3
#define STATE_STAR 4
#define STATE_START 5
#define STATE_HIGHBYTE 6
#define STATE_LOWBYTE 7
// mode command
#define STATE_M 10
#define STATE_MO 11
#define STATE_MOD 12
#define STATE_MODE 13
#define STATE_MODE_1 14
#define STATE_MODE_2 15
#define STATE_MODE_3 16
#define STATE_MODE_4 17
#define STATE_MODE_5 18
#define STATE_MODE_6 19

// dma commands
#define STATE_D 20
#define STATE_DM 21
#define STATE_DMA 22

#define NEXT 255
#define GET_FRAME 254
#define GET_RAW_FRAME 253 // deprecated

// One frame consists of up to 16 subframes to imitate a simple software PWM.
// Each LED has 4-bit brightness. One byte in an incoming frames consists of two half-bytes, describing to 2 LEDs.
// The high half (high nibble) is for the left, low half (low nibble) for the right LED.

// one panel consists of 6 shift registers (6 bytes), format: 16*24 leds
/*
*        1       2
*   1 oooooooo oooooooo
*   2 oooooooo oooooooo
*   3 oooooooo oooooooo
*   4 oooooooo oooooooo
*   5 oooooooo oooooooo
*   6 oooooooo oooooooo
*   7 oooooooo oooooooo
*   8 oooooooo oooooooo
*        3       4
*   1 oooooooo oooooooo
*   2 oooooooo oooooooo
*   3 oooooooo oooooooo
*   4 oooooooo oooooooo
*   5 oooooooo oooooooo
*   6 oooooooo oooooooo
*   7 oooooooo oooooooo
*   8 oooooooo oooooooo
*        5       6
*   1 oooooooo oooooooo
*   2 oooooooo oooooooo
*   3 oooooooo oooooooo
*   4 oooooooo oooooooo
*   5 oooooooo oooooooo
*   6 oooooooo oooooooo
*   7 oooooooo oooooooo
*   8 oooooooo oooooooo
*/

extern struct netif gnetif;
struct tcp_pcb *pcb_tcp;

struct ip_struct {
    uint32_t ip_hex;
    uint8_t a;
    uint8_t b;
    uint8_t c;
    uint8_t d;
};

struct ip_struct my_ip;

char usb_data_out[2000];
//char usb_data_in[100];
char tcp1_status[100];
char tcp2_status[100];
char tcp3_status[100];
//char tcp4_status[400];
//char tcp5_status[400];
//char tcp6_status[400];
uint32_t status_counter = 0;
volatile uint32_t tcp_connection_timeout_counter = 0;

uint32_t current_position = 0; // deprecated?
uint32_t receiving_frame = 0;
uint32_t new_input_frame = 1;
volatile uint32_t new_output_frame = 1;
uint32_t processing_frame = 0;
volatile uint32_t next_frame = 1;
volatile uint32_t dma_swiched = 0;
uint32_t t_fps = 0;
uint32_t t_rps = 0;
uint32_t fps = 0;
uint32_t rps = 0;

uint32_t len = 0;
uint8_t *data;
uint32_t pos = 0;
uint8_t tcp_state = STATE_NONE;
uint8_t tcp_recv_state = NEXT;
uint32_t frame_len = 0;
uint32_t bytes_to_copy = 0;
uint32_t bytes_copied = 0;

uint8_t currentRow = 0;
uint8_t currentPanelRow = 0;
uint8_t currentSubframe = 0;
uint8_t inputBuffer[Y_SIZE*X_SIZE] = {0};
uint8_t frameBuffer[ROWS][COLUMS] = {0};
uint8_t outputBuffer_0[SUBFRAMES*ROWS*SHIFTREGS] = {0};
uint8_t outputBuffer_1[SUBFRAMES*ROWS*SHIFTREGS] = {0};
uint8_t current_buffer = 0; // buffer currently read from
uint8_t use_both_panels = 1; // use one or two panels. using one panel is twice as fast
uint8_t stop_dmas = 1;
uint8_t dma_spi_done = 1;
uint32_t dma_timeout = 0;
volatile uint32_t tim9_counter = 0;
HAL_StatusTypeDef spi2_err = HAL_OK;
HAL_StatusTypeDef spi5_err = HAL_OK;
HAL_StatusTypeDef spi2_error = HAL_OK; // used as flagg for debugging
HAL_StatusTypeDef spi5_error = HAL_OK;

uint8_t startup_pattern = 0;
uint8_t use_subframe_nr = SUBFRAMES;
uint8_t max_fps = 30;
volatile uint32_t milli_counter = 0;
volatile uint32_t milli_max = 0;

/* USER CODE END PV */

void SystemClock_Config(void);
static void MX_GPIO_Init(void);
static void MX_DMA_Init(void);
static void MX_CRC_Init(void);
static void MX_SPI2_Init(void);
static void MX_TIM1_Init(void);
static void MX_TIM2_Init(void);
static void MX_TIM3_Init(void);
static void MX_TIM5_Init(void);
static void MX_TIM8_Init(void);
static void MX_USART1_UART_Init(void);
static void MX_USART6_UART_Init(void);
static void MX_SPI5_Init(void);
static void MX_FMC_Init(void);
static void MX_TIM9_Init(void);

/* USER CODE BEGIN PFP */
/* Private function prototypes -----------------------------------------------*/

static void tcp_setup(void);
static err_t tcp_connection_accepted(void *arg, struct tcp_pcb *newpcb, err_t err);
static err_t tcp_receive_callback(void *arg, struct tcp_pcb *tpcb, struct pbuf *p, err_t err);
static void close_connection(struct tcp_pcb *pcb, char *reason);
static err_t tcp_poll_timeout(void *args,struct tcp_pcb *tpcb);
static uint8_t tcp_StateMachiene(char d);

static void map_inputBuffer_to_frameBuffer();
static void map_frameBuffer_to_outputBuffer(void);
static void test_Pattern_inputBuffer(void);
static void test_Pattern_frameBuffer(void);
static void test_Pattern_outputBuffer(void);
static void reset(void);
static void send_status(void);
static void update_fps(void);
static void update_rps(void);
static void stop_display(void);
static void start_display(void);

void HAL_SPI_TxCpltCallback(SPI_HandleTypeDef * spi);

/* USER CODE END PFP */

int main(void)
{

  /* MCU Configuration----------------------------------------------------------*/

  /* Reset of all peripherals, Initializes the Flash interface and the Systick. */
  HAL_Init();

  /* Configure the system clock */
  SystemClock_Config();

  /* Initialize all configured peripherals */
  MX_GPIO_Init();
  MX_DMA_Init();
  MX_CRC_Init();
  MX_SPI2_Init();
  MX_TIM1_Init();
  MX_TIM2_Init();
  MX_TIM3_Init();
  MX_TIM5_Init();
  MX_TIM8_Init();
  MX_USART1_UART_Init();
  MX_USART6_UART_Init();
  MX_SPI5_Init();
  MX_LWIP_Init();
  MX_USB_DEVICE_Init();
  MX_FMC_Init();
  MX_TIM9_Init();
  /* USER CODE BEGIN 2 */

  HAL_TIM_Base_Start_IT(&htim9);
  stop_display();
  HAL_Delay(2000);
  my_ip.ip_hex = netif_ip4_addr(&gnetif)->addr;
  my_ip.d = (my_ip.ip_hex & 0xff000000) >> 24;
  my_ip.c = (my_ip.ip_hex & 0x00ff0000) >> 16;
  my_ip.b = (my_ip.ip_hex & 0x0000ff00) >> 8;
  my_ip.a = (my_ip.ip_hex & 0x000000ff) >> 0;
  if(USB_WELCOME_MSG) memset(usb_data_out, 0, sizeof(usb_data_out));
  if(USB_WELCOME_MSG) sprintf(usb_data_out,WELCOME_MSG,my_ip.a,my_ip.b,my_ip.c,my_ip.d,VERSION_STRING);
  if(USB_WELCOME_MSG) usb_send_data(usb_data_out,sizeof(usb_data_out),10000);
  milli_max = (uint32_t) 1000.0/max_fps;
  MX_LWIP_Process();
  tcp_setup();
  reset();
  start_display();

  /* USER CODE END 2 */

  /* Infinite loop */
  /* USER CODE BEGIN WHILE */
    while (1) {
    MX_LWIP_Process();
    status_counter++;
    dma_timeout++;
    if(status_counter == 5000000){ send_status(); status_counter = 0;}
    if(spi2_error != HAL_OK || spi5_error != HAL_OK){
        if(USB_SPI_DEBUGG) memset(usb_data_out, 0, sizeof(usb_data_out));
        if(USB_SPI_DEBUGG) sprintf(usb_data_out,"ERROR IN SPI_DMA ROUTINE: \r\nspi2: %d\r\nspi5: %d\r\n",spi2_error,spi5_error);
        if(USB_SPI_DEBUGG) usb_send_data(usb_data_out,sizeof(usb_data_out),10000);
        spi2_error = HAL_OK;
        spi5_error = HAL_OK;
    }
  /* USER CODE END WHILE */

  }

}

void SystemClock_Config(void)
{

  RCC_OscInitTypeDef RCC_OscInitStruct;
  RCC_ClkInitTypeDef RCC_ClkInitStruct;
  RCC_PeriphCLKInitTypeDef PeriphClkInitStruct;

    /**Configure the main internal regulator output voltage
    */
  __HAL_RCC_PWR_CLK_ENABLE();

  __HAL_PWR_VOLTAGESCALING_CONFIG(PWR_REGULATOR_VOLTAGE_SCALE1);

    /**Initializes the CPU, AHB and APB busses clocks
    */
  RCC_OscInitStruct.OscillatorType = RCC_OSCILLATORTYPE_HSE;
  RCC_OscInitStruct.HSEState = RCC_HSE_ON;
  RCC_OscInitStruct.PLL.PLLState = RCC_PLL_ON;
  RCC_OscInitStruct.PLL.PLLSource = RCC_PLLSOURCE_HSE;
  RCC_OscInitStruct.PLL.PLLM = 25;
  RCC_OscInitStruct.PLL.PLLN = 400;
  RCC_OscInitStruct.PLL.PLLP = RCC_PLLP_DIV2;
  RCC_OscInitStruct.PLL.PLLQ = 9;
  if (HAL_RCC_OscConfig(&RCC_OscInitStruct) != HAL_OK)
  {
    _Error_Handler(__FILE__, __LINE__);
  }

    /**Activate the Over-Drive mode
    */
  if (HAL_PWREx_EnableOverDrive() != HAL_OK)
  {
    _Error_Handler(__FILE__, __LINE__);
  }

    /**Initializes the CPU, AHB and APB busses clocks
    */
  RCC_ClkInitStruct.ClockType = RCC_CLOCKTYPE_HCLK|RCC_CLOCKTYPE_SYSCLK
                              |RCC_CLOCKTYPE_PCLK1|RCC_CLOCKTYPE_PCLK2;
  RCC_ClkInitStruct.SYSCLKSource = RCC_SYSCLKSOURCE_PLLCLK;
  RCC_ClkInitStruct.AHBCLKDivider = RCC_SYSCLK_DIV1;
  RCC_ClkInitStruct.APB1CLKDivider = RCC_HCLK_DIV4;
  RCC_ClkInitStruct.APB2CLKDivider = RCC_HCLK_DIV2;

  if (HAL_RCC_ClockConfig(&RCC_ClkInitStruct, FLASH_LATENCY_6) != HAL_OK)
  {
    _Error_Handler(__FILE__, __LINE__);
  }

  PeriphClkInitStruct.PeriphClockSelection = RCC_PERIPHCLK_USART1|RCC_PERIPHCLK_USART6
                              |RCC_PERIPHCLK_CLK48;
  PeriphClkInitStruct.PLLSAI.PLLSAIN = 384;
  PeriphClkInitStruct.PLLSAI.PLLSAIR = 5;
  PeriphClkInitStruct.PLLSAI.PLLSAIQ = 2;
  PeriphClkInitStruct.PLLSAI.PLLSAIP = RCC_PLLSAIP_DIV8;
  PeriphClkInitStruct.PLLSAIDivQ = 1;
  PeriphClkInitStruct.PLLSAIDivR = RCC_PLLSAIDIVR_8;
  PeriphClkInitStruct.Usart1ClockSelection = RCC_USART1CLKSOURCE_PCLK2;
  PeriphClkInitStruct.Usart6ClockSelection = RCC_USART6CLKSOURCE_PCLK2;
  PeriphClkInitStruct.Clk48ClockSelection = RCC_CLK48SOURCE_PLLSAIP;
  if (HAL_RCCEx_PeriphCLKConfig(&PeriphClkInitStruct) != HAL_OK)
  {
    _Error_Handler(__FILE__, __LINE__);
  }

    /**Configure the Systick interrupt time
    */
  HAL_SYSTICK_Config(HAL_RCC_GetHCLKFreq()/1000);

    /**Configure the Systick
    */
  HAL_SYSTICK_CLKSourceConfig(SYSTICK_CLKSOURCE_HCLK);

  /* SysTick_IRQn interrupt configuration */
  HAL_NVIC_SetPriority(SysTick_IRQn, 0, 0);
}

/* CRC init function */
static void MX_CRC_Init(void)
{

  hcrc.Instance = CRC;
  hcrc.Init.DefaultPolynomialUse = DEFAULT_POLYNOMIAL_ENABLE;
  hcrc.Init.DefaultInitValueUse = DEFAULT_INIT_VALUE_ENABLE;
  hcrc.Init.InputDataInversionMode = CRC_INPUTDATA_INVERSION_NONE;
  hcrc.Init.OutputDataInversionMode = CRC_OUTPUTDATA_INVERSION_DISABLE;
  hcrc.InputDataFormat = CRC_INPUTDATA_FORMAT_BYTES;
  if (HAL_CRC_Init(&hcrc) != HAL_OK)
  {
    _Error_Handler(__FILE__, __LINE__);
  }

}

/* SPI2 init function */
static void MX_SPI2_Init(void)
{

  /* SPI2 parameter configuration*/
  hspi2.Instance = SPI2;
  hspi2.Init.Mode = SPI_MODE_MASTER;
  hspi2.Init.Direction = SPI_DIRECTION_2LINES;
  hspi2.Init.DataSize = SPI_DATASIZE_8BIT;
  hspi2.Init.CLKPolarity = SPI_POLARITY_LOW;
  hspi2.Init.CLKPhase = SPI_PHASE_2EDGE;
  hspi2.Init.NSS = SPI_NSS_SOFT;
  hspi2.Init.BaudRatePrescaler = SPI_BAUDRATEPRESCALER_4;
  hspi2.Init.FirstBit = SPI_FIRSTBIT_LSB;
  hspi2.Init.TIMode = SPI_TIMODE_DISABLE;
  hspi2.Init.CRCCalculation = SPI_CRCCALCULATION_DISABLE;
  hspi2.Init.CRCPolynomial = 7;
  hspi2.Init.CRCLength = SPI_CRC_LENGTH_DATASIZE;
  hspi2.Init.NSSPMode = SPI_NSS_PULSE_DISABLE;
  if (HAL_SPI_Init(&hspi2) != HAL_OK)
  {
    _Error_Handler(__FILE__, __LINE__);
  }

}

/* SPI5 init function */
static void MX_SPI5_Init(void)
{

  /* SPI5 parameter configuration*/
  hspi5.Instance = SPI5;
  hspi5.Init.Mode = SPI_MODE_MASTER;
  hspi5.Init.Direction = SPI_DIRECTION_2LINES;
  hspi5.Init.DataSize = SPI_DATASIZE_8BIT;
  hspi5.Init.CLKPolarity = SPI_POLARITY_HIGH;
  hspi5.Init.CLKPhase = SPI_PHASE_2EDGE;
  hspi5.Init.NSS = SPI_NSS_SOFT;
  hspi5.Init.BaudRatePrescaler = SPI_BAUDRATEPRESCALER_8;
  hspi5.Init.FirstBit = SPI_FIRSTBIT_LSB;
  hspi5.Init.TIMode = SPI_TIMODE_DISABLE;
  hspi5.Init.CRCCalculation = SPI_CRCCALCULATION_DISABLE;
  hspi5.Init.CRCPolynomial = 7;
  hspi5.Init.CRCLength = SPI_CRC_LENGTH_DATASIZE;
  hspi5.Init.NSSPMode = SPI_NSS_PULSE_DISABLE;
  if (HAL_SPI_Init(&hspi5) != HAL_OK)
  {
    _Error_Handler(__FILE__, __LINE__);
  }

}

/* TIM1 init function */
static void MX_TIM1_Init(void)
{

  TIM_ClockConfigTypeDef sClockSourceConfig;
  TIM_MasterConfigTypeDef sMasterConfig;

  htim1.Instance = TIM1;
  htim1.Init.Prescaler = 0;
  htim1.Init.CounterMode = TIM_COUNTERMODE_UP;
  htim1.Init.Period = 0;
  htim1.Init.ClockDivision = TIM_CLOCKDIVISION_DIV1;
  htim1.Init.RepetitionCounter = 0;
  htim1.Init.AutoReloadPreload = TIM_AUTORELOAD_PRELOAD_DISABLE;
  if (HAL_TIM_Base_Init(&htim1) != HAL_OK)
  {
    _Error_Handler(__FILE__, __LINE__);
  }

  sClockSourceConfig.ClockSource = TIM_CLOCKSOURCE_INTERNAL;
  if (HAL_TIM_ConfigClockSource(&htim1, &sClockSourceConfig) != HAL_OK)
  {
    _Error_Handler(__FILE__, __LINE__);
  }

  sMasterConfig.MasterOutputTrigger = TIM_TRGO_RESET;
  sMasterConfig.MasterOutputTrigger2 = TIM_TRGO2_RESET;
  sMasterConfig.MasterSlaveMode = TIM_MASTERSLAVEMODE_DISABLE;
  if (HAL_TIMEx_MasterConfigSynchronization(&htim1, &sMasterConfig) != HAL_OK)
  {
    _Error_Handler(__FILE__, __LINE__);
  }

}

/* TIM2 init function */
static void MX_TIM2_Init(void)
{

  TIM_ClockConfigTypeDef sClockSourceConfig;
  TIM_MasterConfigTypeDef sMasterConfig;

  htim2.Instance = TIM2;
  htim2.Init.Prescaler = 0;
  htim2.Init.CounterMode = TIM_COUNTERMODE_UP;
  htim2.Init.Period = 0;
  htim2.Init.ClockDivision = TIM_CLOCKDIVISION_DIV1;
  htim2.Init.AutoReloadPreload = TIM_AUTORELOAD_PRELOAD_DISABLE;
  if (HAL_TIM_Base_Init(&htim2) != HAL_OK)
  {
    _Error_Handler(__FILE__, __LINE__);
  }

  sClockSourceConfig.ClockSource = TIM_CLOCKSOURCE_INTERNAL;
  if (HAL_TIM_ConfigClockSource(&htim2, &sClockSourceConfig) != HAL_OK)
  {
    _Error_Handler(__FILE__, __LINE__);
  }

  sMasterConfig.MasterOutputTrigger = TIM_TRGO_RESET;
  sMasterConfig.MasterSlaveMode = TIM_MASTERSLAVEMODE_DISABLE;
  if (HAL_TIMEx_MasterConfigSynchronization(&htim2, &sMasterConfig) != HAL_OK)
  {
    _Error_Handler(__FILE__, __LINE__);
  }

}

/* TIM3 init function */
static void MX_TIM3_Init(void)
{

  TIM_ClockConfigTypeDef sClockSourceConfig;
  TIM_MasterConfigTypeDef sMasterConfig;

  htim3.Instance = TIM3;
  htim3.Init.Prescaler = 0;
  htim3.Init.CounterMode = TIM_COUNTERMODE_UP;
  htim3.Init.Period = 0;
  htim3.Init.ClockDivision = TIM_CLOCKDIVISION_DIV1;
  htim3.Init.AutoReloadPreload = TIM_AUTORELOAD_PRELOAD_DISABLE;
  if (HAL_TIM_Base_Init(&htim3) != HAL_OK)
  {
    _Error_Handler(__FILE__, __LINE__);
  }

  sClockSourceConfig.ClockSource = TIM_CLOCKSOURCE_INTERNAL;
  if (HAL_TIM_ConfigClockSource(&htim3, &sClockSourceConfig) != HAL_OK)
  {
    _Error_Handler(__FILE__, __LINE__);
  }

  sMasterConfig.MasterOutputTrigger = TIM_TRGO_RESET;
  sMasterConfig.MasterSlaveMode = TIM_MASTERSLAVEMODE_DISABLE;
  if (HAL_TIMEx_MasterConfigSynchronization(&htim3, &sMasterConfig) != HAL_OK)
  {
    _Error_Handler(__FILE__, __LINE__);
  }

}

/* TIM5 init function */
static void MX_TIM5_Init(void)
{

  TIM_ClockConfigTypeDef sClockSourceConfig;
  TIM_MasterConfigTypeDef sMasterConfig;

  htim5.Instance = TIM5;
  htim5.Init.Prescaler = 0;
  htim5.Init.CounterMode = TIM_COUNTERMODE_UP;
  htim5.Init.Period = 0;
  htim5.Init.ClockDivision = TIM_CLOCKDIVISION_DIV1;
  htim5.Init.AutoReloadPreload = TIM_AUTORELOAD_PRELOAD_DISABLE;
  if (HAL_TIM_Base_Init(&htim5) != HAL_OK)
  {
    _Error_Handler(__FILE__, __LINE__);
  }

  sClockSourceConfig.ClockSource = TIM_CLOCKSOURCE_INTERNAL;
  if (HAL_TIM_ConfigClockSource(&htim5, &sClockSourceConfig) != HAL_OK)
  {
    _Error_Handler(__FILE__, __LINE__);
  }

  sMasterConfig.MasterOutputTrigger = TIM_TRGO_RESET;
  sMasterConfig.MasterSlaveMode = TIM_MASTERSLAVEMODE_DISABLE;
  if (HAL_TIMEx_MasterConfigSynchronization(&htim5, &sMasterConfig) != HAL_OK)
  {
    _Error_Handler(__FILE__, __LINE__);
  }

}

/* TIM8 init function */
static void MX_TIM8_Init(void)
{

  TIM_ClockConfigTypeDef sClockSourceConfig;
  TIM_MasterConfigTypeDef sMasterConfig;

  htim8.Instance = TIM8;
  htim8.Init.Prescaler = 0;
  htim8.Init.CounterMode = TIM_COUNTERMODE_UP;
  htim8.Init.Period = 0;
  htim8.Init.ClockDivision = TIM_CLOCKDIVISION_DIV1;
  htim8.Init.RepetitionCounter = 0;
  htim8.Init.AutoReloadPreload = TIM_AUTORELOAD_PRELOAD_DISABLE;
  if (HAL_TIM_Base_Init(&htim8) != HAL_OK)
  {
    _Error_Handler(__FILE__, __LINE__);
  }

  sClockSourceConfig.ClockSource = TIM_CLOCKSOURCE_INTERNAL;
  if (HAL_TIM_ConfigClockSource(&htim8, &sClockSourceConfig) != HAL_OK)
  {
    _Error_Handler(__FILE__, __LINE__);
  }

  sMasterConfig.MasterOutputTrigger = TIM_TRGO_RESET;
  sMasterConfig.MasterOutputTrigger2 = TIM_TRGO2_RESET;
  sMasterConfig.MasterSlaveMode = TIM_MASTERSLAVEMODE_DISABLE;
  if (HAL_TIMEx_MasterConfigSynchronization(&htim8, &sMasterConfig) != HAL_OK)
  {
    _Error_Handler(__FILE__, __LINE__);
  }

}

/* TIM9 init function */
static void MX_TIM9_Init(void)
{

  TIM_ClockConfigTypeDef sClockSourceConfig;

  htim9.Instance = TIM9;
  htim9.Init.Prescaler = 2;
  htim9.Init.CounterMode = TIM_COUNTERMODE_UP;
  htim9.Init.Period = 5000;
  htim9.Init.ClockDivision = TIM_CLOCKDIVISION_DIV1;
  htim9.Init.AutoReloadPreload = TIM_AUTORELOAD_PRELOAD_DISABLE;
  if (HAL_TIM_Base_Init(&htim9) != HAL_OK)
  {
    _Error_Handler(__FILE__, __LINE__);
  }

  sClockSourceConfig.ClockSource = TIM_CLOCKSOURCE_INTERNAL;
  if (HAL_TIM_ConfigClockSource(&htim9, &sClockSourceConfig) != HAL_OK)
  {
    _Error_Handler(__FILE__, __LINE__);
  }

}

/* USART1 init function */
static void MX_USART1_UART_Init(void)
{

  huart1.Instance = USART1;
  huart1.Init.BaudRate = 115200;
  huart1.Init.WordLength = UART_WORDLENGTH_8B;
  huart1.Init.StopBits = UART_STOPBITS_1;
  huart1.Init.Parity = UART_PARITY_NONE;
  huart1.Init.Mode = UART_MODE_TX_RX;
  huart1.Init.HwFlowCtl = UART_HWCONTROL_NONE;
  huart1.Init.OverSampling = UART_OVERSAMPLING_16;
  huart1.Init.OneBitSampling = UART_ONE_BIT_SAMPLE_DISABLE;
  huart1.AdvancedInit.AdvFeatureInit = UART_ADVFEATURE_NO_INIT;
  if (HAL_UART_Init(&huart1) != HAL_OK)
  {
    _Error_Handler(__FILE__, __LINE__);
  }

}

/* USART6 init function */
static void MX_USART6_UART_Init(void)
{

  huart6.Instance = USART6;
  huart6.Init.BaudRate = 115200;
  huart6.Init.WordLength = UART_WORDLENGTH_8B;
  huart6.Init.StopBits = UART_STOPBITS_1;
  huart6.Init.Parity = UART_PARITY_NONE;
  huart6.Init.Mode = UART_MODE_TX_RX;
  huart6.Init.HwFlowCtl = UART_HWCONTROL_NONE;
  huart6.Init.OverSampling = UART_OVERSAMPLING_16;
  huart6.Init.OneBitSampling = UART_ONE_BIT_SAMPLE_DISABLE;
  huart6.AdvancedInit.AdvFeatureInit = UART_ADVFEATURE_NO_INIT;
  if (HAL_UART_Init(&huart6) != HAL_OK)
  {
    _Error_Handler(__FILE__, __LINE__);
  }

}

static void MX_DMA_Init(void)
{
  /* DMA controller clock enable */
  __HAL_RCC_DMA2_CLK_ENABLE();
  __HAL_RCC_DMA1_CLK_ENABLE();

  /* Configure DMA request hdma_memtomem_dma2_stream4 on DMA2_Stream4 */
  hdma_memtomem_dma2_stream4.Instance = DMA2_Stream4;
  hdma_memtomem_dma2_stream4.Init.Channel = DMA_CHANNEL_0;
  hdma_memtomem_dma2_stream4.Init.Direction = DMA_MEMORY_TO_MEMORY;
  hdma_memtomem_dma2_stream4.Init.PeriphInc = DMA_PINC_ENABLE;
  hdma_memtomem_dma2_stream4.Init.MemInc = DMA_MINC_ENABLE;
  hdma_memtomem_dma2_stream4.Init.PeriphDataAlignment = DMA_PDATAALIGN_BYTE;
  hdma_memtomem_dma2_stream4.Init.MemDataAlignment = DMA_MDATAALIGN_BYTE;
  hdma_memtomem_dma2_stream4.Init.Mode = DMA_NORMAL;
  hdma_memtomem_dma2_stream4.Init.Priority = DMA_PRIORITY_LOW;
  hdma_memtomem_dma2_stream4.Init.FIFOMode = DMA_FIFOMODE_ENABLE;
  hdma_memtomem_dma2_stream4.Init.FIFOThreshold = DMA_FIFO_THRESHOLD_FULL;
  hdma_memtomem_dma2_stream4.Init.MemBurst = DMA_MBURST_SINGLE;
  hdma_memtomem_dma2_stream4.Init.PeriphBurst = DMA_PBURST_SINGLE;
  if (HAL_DMA_Init(&hdma_memtomem_dma2_stream4) != HAL_OK)
  {
    _Error_Handler(__FILE__, __LINE__);
  }

  /* DMA interrupt init */
  /* DMA1_Stream4_IRQn interrupt configuration */
  HAL_NVIC_SetPriority(DMA1_Stream4_IRQn, 0, 0);
  HAL_NVIC_EnableIRQ(DMA1_Stream4_IRQn);
  /* DMA2_Stream6_IRQn interrupt configuration */
  HAL_NVIC_SetPriority(DMA2_Stream6_IRQn, 0, 0);
  HAL_NVIC_EnableIRQ(DMA2_Stream6_IRQn);

}
/* FMC initialization function */
static void MX_FMC_Init(void)
{
  FMC_SDRAM_TimingTypeDef SdramTiming;

  /** Perform the SDRAM1 memory initialization sequence
  */
  hsdram1.Instance = FMC_SDRAM_DEVICE;
  /* hsdram1.Init */
  hsdram1.Init.SDBank = FMC_SDRAM_BANK1;
  hsdram1.Init.ColumnBitsNumber = FMC_SDRAM_COLUMN_BITS_NUM_8;
  hsdram1.Init.RowBitsNumber = FMC_SDRAM_ROW_BITS_NUM_12;
  hsdram1.Init.MemoryDataWidth = FMC_SDRAM_MEM_BUS_WIDTH_16;
  hsdram1.Init.InternalBankNumber = FMC_SDRAM_INTERN_BANKS_NUM_4;
  hsdram1.Init.CASLatency = FMC_SDRAM_CAS_LATENCY_3;
  hsdram1.Init.WriteProtection = FMC_SDRAM_WRITE_PROTECTION_DISABLE;
  hsdram1.Init.SDClockPeriod = FMC_SDRAM_CLOCK_PERIOD_2;
  hsdram1.Init.ReadBurst = FMC_SDRAM_RBURST_ENABLE;
  hsdram1.Init.ReadPipeDelay = FMC_SDRAM_RPIPE_DELAY_0;
  /* SdramTiming */
  SdramTiming.LoadToActiveDelay = 2;
  SdramTiming.ExitSelfRefreshDelay = 7;
  SdramTiming.SelfRefreshTime = 4;
  SdramTiming.RowCycleDelay = 7;
  SdramTiming.WriteRecoveryTime = 3;
  SdramTiming.RPDelay = 2;
  SdramTiming.RCDDelay = 2;

  if (HAL_SDRAM_Init(&hsdram1, &SdramTiming) != HAL_OK)
  {
    _Error_Handler(__FILE__, __LINE__);
  }

}

/** Configure pins
     PE4   ------> LTDC_B0
     PE2   ------> QUADSPI_BK1_IO2
     PB8   ------> I2C1_SCL
     PB5   ------> USB_OTG_HS_ULPI_D7
     PD7   ------> SPDIFRX_IN0
     PC12   ------> SDMMC1_CK
     PE5   ------> DCMI_D6
     PE6   ------> DCMI_D7
     PB9   ------> I2C1_SDA
     PB6   ------> QUADSPI_BK1_NCS
     PJ13   ------> LTDC_B1
     PC11   ------> SDMMC1_D3
     PC10   ------> SDMMC1_D2
     PI4   ------> SAI2_MCLK_A
     PK7   ------> LTDC_DE
     PK6   ------> LTDC_B7
     PK5   ------> LTDC_B6
     PG12   ------> LTDC_B4
     PG10   ------> SAI2_SD_B
     PJ14   ------> LTDC_B2
     PD3   ------> DCMI_D5
     PI5   ------> SAI2_SCK_A
     PI7   ------> SAI2_FS_A
     PI10   ------> LTDC_HSYNC
     PI6   ------> SAI2_SD_A
     PK4   ------> LTDC_B5
     PG9   ------> DCMI_VSYNC
     PJ15   ------> LTDC_B3
     PD2   ------> SDMMC1_CMD
     PI9   ------> LTDC_VSYNC
     PH14   ------> DCMI_D4
     PK1   ------> LTDC_G6
     PK2   ------> LTDC_G7
     PC9   ------> SDMMC1_D1
     PI15   ------> LTDC_R0
     PJ11   ------> LTDC_G4
     PK0   ------> LTDC_G5
     PC8   ------> SDMMC1_D0
     PI14   ------> LTDC_CLK
     PH4   ------> USB_OTG_HS_ULPI_NXT
     PJ8   ------> LTDC_G1
     PJ10   ------> LTDC_G3
     PJ7   ------> LTDC_G0
     PJ9   ------> LTDC_G2
     PF6   ------> ADC3_IN4
     PJ6   ------> LTDC_R7
     PB13   ------> USB_OTG_HS_ULPI_D6
     PB12   ------> USB_OTG_HS_ULPI_D5
     PC0   ------> USB_OTG_HS_ULPI_STP
     PC2   ------> USB_OTG_HS_ULPI_DIR
     PB2   ------> QUADSPI_CLK
     PJ4   ------> LTDC_R5
     PD12   ------> QUADSPI_BK1_IO1
     PD13   ------> QUADSPI_BK1_IO3
     PJ5   ------> LTDC_R6
     PH12   ------> DCMI_D3
     PA0/WKUP   ------> ADCx_IN0
     PA4   ------> DCMI_HSYNC
     PJ3   ------> LTDC_R4
     PD11   ------> QUADSPI_BK1_IO0
     PH7   ------> I2C3_SCL
     PH9   ------> DCMI_D0
     PH11   ------> DCMI_D2
     PA6   ------> DCMI_PIXCLK
     PA5   ------> USB_OTG_HS_ULPI_CK
     PJ2   ------> LTDC_R3
     PB10   ------> USB_OTG_HS_ULPI_D3
     PH8   ------> I2C3_SDA
     PH10   ------> DCMI_D1
     PA3   ------> USB_OTG_HS_ULPI_D0
     PB1   ------> USB_OTG_HS_ULPI_D2
     PB0   ------> USB_OTG_HS_ULPI_D1
     PJ0   ------> LTDC_R1
     PJ1   ------> LTDC_R2
     PB11   ------> USB_OTG_HS_ULPI_D4
*/
static void MX_GPIO_Init(void)
{

  GPIO_InitTypeDef GPIO_InitStruct;

  /* GPIO Ports Clock Enable */
  __HAL_RCC_GPIOE_CLK_ENABLE();
  __HAL_RCC_GPIOG_CLK_ENABLE();
  __HAL_RCC_GPIOB_CLK_ENABLE();
  __HAL_RCC_GPIOD_CLK_ENABLE();
  __HAL_RCC_GPIOC_CLK_ENABLE();
  __HAL_RCC_GPIOA_CLK_ENABLE();
  __HAL_RCC_GPIOJ_CLK_ENABLE();
  __HAL_RCC_GPIOI_CLK_ENABLE();
  __HAL_RCC_GPIOK_CLK_ENABLE();
  __HAL_RCC_GPIOF_CLK_ENABLE();
  __HAL_RCC_GPIOH_CLK_ENABLE();

  /*Configure GPIO pin Output Level */
  HAL_GPIO_WritePin(GPIOB, row1_Pin|latch_Pin, GPIO_PIN_RESET);

  /*Configure GPIO pin Output Level */
  HAL_GPIO_WritePin(row7_GPIO_Port, row7_Pin, GPIO_PIN_RESET);

  /*Configure GPIO pin Output Level */
  HAL_GPIO_WritePin(OTG_FS_PowerSwitchOn_GPIO_Port, OTG_FS_PowerSwitchOn_Pin, GPIO_PIN_SET);

  /*Configure GPIO pin Output Level */
  HAL_GPIO_WritePin(GPIOI, row5_Pin|row6_Pin|row3_Pin, GPIO_PIN_RESET);

  /*Configure GPIO pin Output Level */
  HAL_GPIO_WritePin(LCD_BL_CTRL_GPIO_Port, LCD_BL_CTRL_Pin, GPIO_PIN_SET);

  /*Configure GPIO pin Output Level */
  HAL_GPIO_WritePin(LCD_DISP_GPIO_Port, LCD_DISP_Pin, GPIO_PIN_SET);

  /*Configure GPIO pin Output Level */
  HAL_GPIO_WritePin(GPIOH, DCMI_PWR_EN_Pin|row4_Pin, GPIO_PIN_RESET);

  /*Configure GPIO pin Output Level */
  HAL_GPIO_WritePin(bank_mode_GPIO_Port, bank_mode_Pin, GPIO_PIN_SET);

  /*Configure GPIO pin Output Level */
  HAL_GPIO_WritePin(GPIOG, row2_Pin|row0_Pin|EXT_RST_Pin, GPIO_PIN_RESET);

  /*Configure GPIO pin Output Level */
  HAL_GPIO_WritePin(GPIOF, CS2_Pin|bank_sel_Pin, GPIO_PIN_RESET);

  /*Configure GPIO pin : LCD_B0_Pin */
  GPIO_InitStruct.Pin = LCD_B0_Pin;
  GPIO_InitStruct.Mode = GPIO_MODE_AF_PP;
  GPIO_InitStruct.Pull = GPIO_NOPULL;
  GPIO_InitStruct.Speed = GPIO_SPEED_FREQ_LOW;
  GPIO_InitStruct.Alternate = GPIO_AF14_LTDC;
  HAL_GPIO_Init(LCD_B0_GPIO_Port, &GPIO_InitStruct);

  /*Configure GPIO pin : OTG_HS_OverCurrent_Pin */
  GPIO_InitStruct.Pin = OTG_HS_OverCurrent_Pin;
  GPIO_InitStruct.Mode = GPIO_MODE_INPUT;
  GPIO_InitStruct.Pull = GPIO_NOPULL;
  HAL_GPIO_Init(OTG_HS_OverCurrent_GPIO_Port, &GPIO_InitStruct);

  /*Configure GPIO pin : QSPI_D2_Pin */
  GPIO_InitStruct.Pin = QSPI_D2_Pin;
  GPIO_InitStruct.Mode = GPIO_MODE_AF_PP;
  GPIO_InitStruct.Pull = GPIO_NOPULL;
  GPIO_InitStruct.Speed = GPIO_SPEED_FREQ_VERY_HIGH;
  GPIO_InitStruct.Alternate = GPIO_AF9_QUADSPI;
  HAL_GPIO_Init(QSPI_D2_GPIO_Port, &GPIO_InitStruct);

  /*Configure GPIO pins : ARDUINO_SCL_D15_Pin ARDUINO_SDA_D14_Pin */
  GPIO_InitStruct.Pin = ARDUINO_SCL_D15_Pin|ARDUINO_SDA_D14_Pin;
  GPIO_InitStruct.Mode = GPIO_MODE_AF_OD;
  GPIO_InitStruct.Pull = GPIO_PULLUP;
  GPIO_InitStruct.Speed = GPIO_SPEED_FREQ_LOW;
  GPIO_InitStruct.Alternate = GPIO_AF4_I2C1;
  HAL_GPIO_Init(GPIOB, &GPIO_InitStruct);

  /*Configure GPIO pins : ULPI_D7_Pin ULPI_D6_Pin ULPI_D5_Pin ULPI_D3_Pin
                           ULPI_D2_Pin ULPI_D1_Pin ULPI_D4_Pin */
  GPIO_InitStruct.Pin = ULPI_D7_Pin|ULPI_D6_Pin|ULPI_D5_Pin|ULPI_D3_Pin
                          |ULPI_D2_Pin|ULPI_D1_Pin|ULPI_D4_Pin;
  GPIO_InitStruct.Mode = GPIO_MODE_AF_PP;
  GPIO_InitStruct.Pull = GPIO_NOPULL;
  GPIO_InitStruct.Speed = GPIO_SPEED_FREQ_VERY_HIGH;
  GPIO_InitStruct.Alternate = GPIO_AF10_OTG_HS;
  HAL_GPIO_Init(GPIOB, &GPIO_InitStruct);

  /*Configure GPIO pins : row1_Pin latch_Pin */
  GPIO_InitStruct.Pin = row1_Pin|latch_Pin;
  GPIO_InitStruct.Mode = GPIO_MODE_OUTPUT_PP;
  GPIO_InitStruct.Pull = GPIO_NOPULL;
  GPIO_InitStruct.Speed = GPIO_SPEED_FREQ_LOW;
  HAL_GPIO_Init(GPIOB, &GPIO_InitStruct);

  /*Configure GPIO pin : SPDIF_RX0_Pin */
  GPIO_InitStruct.Pin = SPDIF_RX0_Pin;
  GPIO_InitStruct.Mode = GPIO_MODE_AF_PP;
  GPIO_InitStruct.Pull = GPIO_NOPULL;
  GPIO_InitStruct.Speed = GPIO_SPEED_FREQ_LOW;
  GPIO_InitStruct.Alternate = GPIO_AF8_SPDIFRX;
  HAL_GPIO_Init(SPDIF_RX0_GPIO_Port, &GPIO_InitStruct);

  /*Configure GPIO pins : SDMMC_CK_Pin SDMMC_D3_Pin SDMMC_D2_Pin PC9
                           PC8 */
  GPIO_InitStruct.Pin = SDMMC_CK_Pin|SDMMC_D3_Pin|SDMMC_D2_Pin|GPIO_PIN_9
                          |GPIO_PIN_8;
  GPIO_InitStruct.Mode = GPIO_MODE_AF_PP;
  GPIO_InitStruct.Pull = GPIO_NOPULL;
  GPIO_InitStruct.Speed = GPIO_SPEED_FREQ_VERY_HIGH;
  GPIO_InitStruct.Alternate = GPIO_AF12_SDMMC1;
  HAL_GPIO_Init(GPIOC, &GPIO_InitStruct);

  /*Configure GPIO pins : row7_Pin bank_mode_Pin */
  GPIO_InitStruct.Pin = row7_Pin|bank_mode_Pin;
  GPIO_InitStruct.Mode = GPIO_MODE_OUTPUT_PP;
  GPIO_InitStruct.Pull = GPIO_NOPULL;
  GPIO_InitStruct.Speed = GPIO_SPEED_FREQ_LOW;
  HAL_GPIO_Init(GPIOA, &GPIO_InitStruct);

  /*Configure GPIO pins : DCMI_D6_Pin DCMI_D7_Pin */
  GPIO_InitStruct.Pin = DCMI_D6_Pin|DCMI_D7_Pin;
  GPIO_InitStruct.Mode = GPIO_MODE_AF_PP;
  GPIO_InitStruct.Pull = GPIO_NOPULL;
  GPIO_InitStruct.Speed = GPIO_SPEED_FREQ_LOW;
  GPIO_InitStruct.Alternate = GPIO_AF13_DCMI;
  HAL_GPIO_Init(GPIOE, &GPIO_InitStruct);

  /*Configure GPIO pin : QSPI_NCS_Pin */
  GPIO_InitStruct.Pin = QSPI_NCS_Pin;
  GPIO_InitStruct.Mode = GPIO_MODE_AF_PP;
  GPIO_InitStruct.Pull = GPIO_NOPULL;
  GPIO_InitStruct.Speed = GPIO_SPEED_FREQ_VERY_HIGH;
  GPIO_InitStruct.Alternate = GPIO_AF10_QUADSPI;
  HAL_GPIO_Init(QSPI_NCS_GPIO_Port, &GPIO_InitStruct);

  /*Configure GPIO pins : LCD_B1_Pin LCD_B2_Pin LCD_B3_Pin LCD_G4_Pin
                           LCD_G1_Pin LCD_G3_Pin LCD_G0_Pin LCD_G2_Pin
                           LCD_R7_Pin LCD_R5_Pin LCD_R6_Pin LCD_R4_Pin
                           LCD_R3_Pin LCD_R1_Pin LCD_R2_Pin */
  GPIO_InitStruct.Pin = LCD_B1_Pin|LCD_B2_Pin|LCD_B3_Pin|LCD_G4_Pin
                          |LCD_G1_Pin|LCD_G3_Pin|LCD_G0_Pin|LCD_G2_Pin
                          |LCD_R7_Pin|LCD_R5_Pin|LCD_R6_Pin|LCD_R4_Pin
                          |LCD_R3_Pin|LCD_R1_Pin|LCD_R2_Pin;
  GPIO_InitStruct.Mode = GPIO_MODE_AF_PP;
  GPIO_InitStruct.Pull = GPIO_NOPULL;
  GPIO_InitStruct.Speed = GPIO_SPEED_FREQ_LOW;
  GPIO_InitStruct.Alternate = GPIO_AF14_LTDC;
  HAL_GPIO_Init(GPIOJ, &GPIO_InitStruct);

  /*Configure GPIO pin : OTG_FS_VBUS_Pin */
  GPIO_InitStruct.Pin = OTG_FS_VBUS_Pin;
  GPIO_InitStruct.Mode = GPIO_MODE_INPUT;
  GPIO_InitStruct.Pull = GPIO_NOPULL;
  HAL_GPIO_Init(OTG_FS_VBUS_GPIO_Port, &GPIO_InitStruct);

  /*Configure GPIO pin : Audio_INT_Pin */
  GPIO_InitStruct.Pin = Audio_INT_Pin;
  GPIO_InitStruct.Mode = GPIO_MODE_EVT_RISING;
  GPIO_InitStruct.Pull = GPIO_NOPULL;
  HAL_GPIO_Init(Audio_INT_GPIO_Port, &GPIO_InitStruct);

  /*Configure GPIO pins : SAI2_MCLKA_Pin SAI2_SCKA_Pin SAI2_FSA_Pin SAI2_SDA_Pin */
  GPIO_InitStruct.Pin = SAI2_MCLKA_Pin|SAI2_SCKA_Pin|SAI2_FSA_Pin|SAI2_SDA_Pin;
  GPIO_InitStruct.Mode = GPIO_MODE_AF_PP;
  GPIO_InitStruct.Pull = GPIO_NOPULL;
  GPIO_InitStruct.Speed = GPIO_SPEED_FREQ_LOW;
  GPIO_InitStruct.Alternate = GPIO_AF10_SAI2;
  HAL_GPIO_Init(GPIOI, &GPIO_InitStruct);

  /*Configure GPIO pins : LCD_DE_Pin LCD_B7_Pin LCD_B6_Pin LCD_B5_Pin
                           LCD_G6_Pin LCD_G7_Pin LCD_G5_Pin */
  GPIO_InitStruct.Pin = LCD_DE_Pin|LCD_B7_Pin|LCD_B6_Pin|LCD_B5_Pin
                          |LCD_G6_Pin|LCD_G7_Pin|LCD_G5_Pin;
  GPIO_InitStruct.Mode = GPIO_MODE_AF_PP;
  GPIO_InitStruct.Pull = GPIO_NOPULL;
  GPIO_InitStruct.Speed = GPIO_SPEED_FREQ_LOW;
  GPIO_InitStruct.Alternate = GPIO_AF14_LTDC;
  HAL_GPIO_Init(GPIOK, &GPIO_InitStruct);

  /*Configure GPIO pin : LCD_B4_Pin */
  GPIO_InitStruct.Pin = LCD_B4_Pin;
  GPIO_InitStruct.Mode = GPIO_MODE_AF_PP;
  GPIO_InitStruct.Pull = GPIO_NOPULL;
  GPIO_InitStruct.Speed = GPIO_SPEED_FREQ_LOW;
  GPIO_InitStruct.Alternate = GPIO_AF9_LTDC;
  HAL_GPIO_Init(LCD_B4_GPIO_Port, &GPIO_InitStruct);

  /*Configure GPIO pin : SAI2_SDB_Pin */
  GPIO_InitStruct.Pin = SAI2_SDB_Pin;
  GPIO_InitStruct.Mode = GPIO_MODE_AF_PP;
  GPIO_InitStruct.Pull = GPIO_NOPULL;
  GPIO_InitStruct.Speed = GPIO_SPEED_FREQ_LOW;
  GPIO_InitStruct.Alternate = GPIO_AF10_SAI2;
  HAL_GPIO_Init(SAI2_SDB_GPIO_Port, &GPIO_InitStruct);

  /*Configure GPIO pin : OTG_FS_PowerSwitchOn_Pin */
  GPIO_InitStruct.Pin = OTG_FS_PowerSwitchOn_Pin;
  GPIO_InitStruct.Mode = GPIO_MODE_OUTPUT_PP;
  GPIO_InitStruct.Pull = GPIO_NOPULL;
  GPIO_InitStruct.Speed = GPIO_SPEED_FREQ_LOW;
  HAL_GPIO_Init(OTG_FS_PowerSwitchOn_GPIO_Port, &GPIO_InitStruct);

  /*Configure GPIO pin : DCMI_D5_Pin */
  GPIO_InitStruct.Pin = DCMI_D5_Pin;
  GPIO_InitStruct.Mode = GPIO_MODE_AF_PP;
  GPIO_InitStruct.Pull = GPIO_NOPULL;
  GPIO_InitStruct.Speed = GPIO_SPEED_FREQ_LOW;
  GPIO_InitStruct.Alternate = GPIO_AF13_DCMI;
  HAL_GPIO_Init(DCMI_D5_GPIO_Port, &GPIO_InitStruct);

  /*Configure GPIO pins : row5_Pin row6_Pin LCD_DISP_Pin row3_Pin */
  GPIO_InitStruct.Pin = row5_Pin|row6_Pin|LCD_DISP_Pin|row3_Pin;
  GPIO_InitStruct.Mode = GPIO_MODE_OUTPUT_PP;
  GPIO_InitStruct.Pull = GPIO_NOPULL;
  GPIO_InitStruct.Speed = GPIO_SPEED_FREQ_LOW;
  HAL_GPIO_Init(GPIOI, &GPIO_InitStruct);

  /*Configure GPIO pin : uSD_Detect_Pin */
  GPIO_InitStruct.Pin = uSD_Detect_Pin;
  GPIO_InitStruct.Mode = GPIO_MODE_INPUT;
  GPIO_InitStruct.Pull = GPIO_NOPULL;
  HAL_GPIO_Init(uSD_Detect_GPIO_Port, &GPIO_InitStruct);

  /*Configure GPIO pins : LCD_HSYNC_Pin LCD_VSYNC_Pin LCD_R0_Pin LCD_CLK_Pin */
  GPIO_InitStruct.Pin = LCD_HSYNC_Pin|LCD_VSYNC_Pin|LCD_R0_Pin|LCD_CLK_Pin;
  GPIO_InitStruct.Mode = GPIO_MODE_AF_PP;
  GPIO_InitStruct.Pull = GPIO_NOPULL;
  GPIO_InitStruct.Speed = GPIO_SPEED_FREQ_LOW;
  GPIO_InitStruct.Alternate = GPIO_AF14_LTDC;
  HAL_GPIO_Init(GPIOI, &GPIO_InitStruct);

  /*Configure GPIO pin : LCD_BL_CTRL_Pin */
  GPIO_InitStruct.Pin = LCD_BL_CTRL_Pin;
  GPIO_InitStruct.Mode = GPIO_MODE_OUTPUT_PP;
  GPIO_InitStruct.Pull = GPIO_NOPULL;
  GPIO_InitStruct.Speed = GPIO_SPEED_FREQ_LOW;
  HAL_GPIO_Init(LCD_BL_CTRL_GPIO_Port, &GPIO_InitStruct);

  /*Configure GPIO pin : DCMI_VSYNC_Pin */
  GPIO_InitStruct.Pin = DCMI_VSYNC_Pin;
  GPIO_InitStruct.Mode = GPIO_MODE_AF_PP;
  GPIO_InitStruct.Pull = GPIO_NOPULL;
  GPIO_InitStruct.Speed = GPIO_SPEED_FREQ_LOW;
  GPIO_InitStruct.Alternate = GPIO_AF13_DCMI;
  HAL_GPIO_Init(DCMI_VSYNC_GPIO_Port, &GPIO_InitStruct);

  /*Configure GPIO pin : OTG_FS_OverCurrent_Pin */
  GPIO_InitStruct.Pin = OTG_FS_OverCurrent_Pin;
  GPIO_InitStruct.Mode = GPIO_MODE_INPUT;
  GPIO_InitStruct.Pull = GPIO_NOPULL;
  HAL_GPIO_Init(OTG_FS_OverCurrent_GPIO_Port, &GPIO_InitStruct);

  /*Configure GPIO pin : SDMMC_CMD_Pin */
  GPIO_InitStruct.Pin = SDMMC_CMD_Pin;
  GPIO_InitStruct.Mode = GPIO_MODE_AF_PP;
  GPIO_InitStruct.Pull = GPIO_NOPULL;
  GPIO_InitStruct.Speed = GPIO_SPEED_FREQ_VERY_HIGH;
  GPIO_InitStruct.Alternate = GPIO_AF12_SDMMC1;
  HAL_GPIO_Init(SDMMC_CMD_GPIO_Port, &GPIO_InitStruct);

  /*Configure GPIO pins : TP3_Pin NC2_Pin */
  GPIO_InitStruct.Pin = TP3_Pin|NC2_Pin;
  GPIO_InitStruct.Mode = GPIO_MODE_INPUT;
  GPIO_InitStruct.Pull = GPIO_NOPULL;
  HAL_GPIO_Init(GPIOH, &GPIO_InitStruct);

  /*Configure GPIO pins : DCMI_PWR_EN_Pin row4_Pin */
  GPIO_InitStruct.Pin = DCMI_PWR_EN_Pin|row4_Pin;
  GPIO_InitStruct.Mode = GPIO_MODE_OUTPUT_PP;
  GPIO_InitStruct.Pull = GPIO_NOPULL;
  GPIO_InitStruct.Speed = GPIO_SPEED_FREQ_LOW;
  HAL_GPIO_Init(GPIOH, &GPIO_InitStruct);

  /*Configure GPIO pins : DCMI_D4_Pin DCMI_D3_Pin DCMI_D0_Pin DCMI_D2_Pin
                           DCMI_D1_Pin */
  GPIO_InitStruct.Pin = DCMI_D4_Pin|DCMI_D3_Pin|DCMI_D0_Pin|DCMI_D2_Pin
                          |DCMI_D1_Pin;
  GPIO_InitStruct.Mode = GPIO_MODE_AF_PP;
  GPIO_InitStruct.Pull = GPIO_NOPULL;
  GPIO_InitStruct.Speed = GPIO_SPEED_FREQ_LOW;
  GPIO_InitStruct.Alternate = GPIO_AF13_DCMI;
  HAL_GPIO_Init(GPIOH, &GPIO_InitStruct);

  /*Configure GPIO pin : LCD_INT_Pin */
  GPIO_InitStruct.Pin = LCD_INT_Pin;
  GPIO_InitStruct.Mode = GPIO_MODE_EVT_RISING;
  GPIO_InitStruct.Pull = GPIO_NOPULL;
  HAL_GPIO_Init(LCD_INT_GPIO_Port, &GPIO_InitStruct);

  /*Configure GPIO pin : ULPI_NXT_Pin */
  GPIO_InitStruct.Pin = ULPI_NXT_Pin;
  GPIO_InitStruct.Mode = GPIO_MODE_AF_PP;
  GPIO_InitStruct.Pull = GPIO_NOPULL;
  GPIO_InitStruct.Speed = GPIO_SPEED_FREQ_VERY_HIGH;
  GPIO_InitStruct.Alternate = GPIO_AF10_OTG_HS;
  HAL_GPIO_Init(ULPI_NXT_GPIO_Port, &GPIO_InitStruct);

  /*Configure GPIO pins : row2_Pin row0_Pin EXT_RST_Pin */
  GPIO_InitStruct.Pin = row2_Pin|row0_Pin|EXT_RST_Pin;
  GPIO_InitStruct.Mode = GPIO_MODE_OUTPUT_PP;
  GPIO_InitStruct.Pull = GPIO_NOPULL;
  GPIO_InitStruct.Speed = GPIO_SPEED_FREQ_LOW;
  HAL_GPIO_Init(GPIOG, &GPIO_InitStruct);

  /*Configure GPIO pin : ARDUINO_A5_Pin */
  GPIO_InitStruct.Pin = ARDUINO_A5_Pin;
  GPIO_InitStruct.Mode = GPIO_MODE_ANALOG;
  GPIO_InitStruct.Pull = GPIO_NOPULL;
  HAL_GPIO_Init(ARDUINO_A5_GPIO_Port, &GPIO_InitStruct);

  /*Configure GPIO pins : CS2_Pin bank_sel_Pin */
  GPIO_InitStruct.Pin = CS2_Pin|bank_sel_Pin;
  GPIO_InitStruct.Mode = GPIO_MODE_OUTPUT_PP;
  GPIO_InitStruct.Pull = GPIO_NOPULL;
  GPIO_InitStruct.Speed = GPIO_SPEED_FREQ_LOW;
  HAL_GPIO_Init(GPIOF, &GPIO_InitStruct);

  /*Configure GPIO pins : ULPI_STP_Pin ULPI_DIR_Pin */
  GPIO_InitStruct.Pin = ULPI_STP_Pin|ULPI_DIR_Pin;
  GPIO_InitStruct.Mode = GPIO_MODE_AF_PP;
  GPIO_InitStruct.Pull = GPIO_NOPULL;
  GPIO_InitStruct.Speed = GPIO_SPEED_FREQ_VERY_HIGH;
  GPIO_InitStruct.Alternate = GPIO_AF10_OTG_HS;
  HAL_GPIO_Init(GPIOC, &GPIO_InitStruct);

  /*Configure GPIO pin : PB2 */
  GPIO_InitStruct.Pin = GPIO_PIN_2;
  GPIO_InitStruct.Mode = GPIO_MODE_AF_PP;
  GPIO_InitStruct.Pull = GPIO_NOPULL;
  GPIO_InitStruct.Speed = GPIO_SPEED_FREQ_VERY_HIGH;
  GPIO_InitStruct.Alternate = GPIO_AF9_QUADSPI;
  HAL_GPIO_Init(GPIOB, &GPIO_InitStruct);

  /*Configure GPIO pins : QSPI_D1_Pin QSPI_D3_Pin QSPI_D0_Pin */
  GPIO_InitStruct.Pin = QSPI_D1_Pin|QSPI_D3_Pin|QSPI_D0_Pin;
  GPIO_InitStruct.Mode = GPIO_MODE_AF_PP;
  GPIO_InitStruct.Pull = GPIO_NOPULL;
  GPIO_InitStruct.Speed = GPIO_SPEED_FREQ_VERY_HIGH;
  GPIO_InitStruct.Alternate = GPIO_AF9_QUADSPI;
  HAL_GPIO_Init(GPIOD, &GPIO_InitStruct);

  /*Configure GPIO pin : RMII_RXER_Pin */
  GPIO_InitStruct.Pin = RMII_RXER_Pin;
  GPIO_InitStruct.Mode = GPIO_MODE_INPUT;
  GPIO_InitStruct.Pull = GPIO_NOPULL;
  HAL_GPIO_Init(RMII_RXER_GPIO_Port, &GPIO_InitStruct);

  /*Configure GPIO pin : ARDUINO_A0_Pin */
  GPIO_InitStruct.Pin = ARDUINO_A0_Pin;
  GPIO_InitStruct.Mode = GPIO_MODE_ANALOG;
  GPIO_InitStruct.Pull = GPIO_NOPULL;
  HAL_GPIO_Init(ARDUINO_A0_GPIO_Port, &GPIO_InitStruct);

  /*Configure GPIO pins : DCMI_HSYNC_Pin PA6 */
  GPIO_InitStruct.Pin = DCMI_HSYNC_Pin|GPIO_PIN_6;
  GPIO_InitStruct.Mode = GPIO_MODE_AF_PP;
  GPIO_InitStruct.Pull = GPIO_NOPULL;
  GPIO_InitStruct.Speed = GPIO_SPEED_FREQ_LOW;
  GPIO_InitStruct.Alternate = GPIO_AF13_DCMI;
  HAL_GPIO_Init(GPIOA, &GPIO_InitStruct);

  /*Configure GPIO pins : LCD_SCL_Pin LCD_SDA_Pin */
  GPIO_InitStruct.Pin = LCD_SCL_Pin|LCD_SDA_Pin;
  GPIO_InitStruct.Mode = GPIO_MODE_AF_OD;
  GPIO_InitStruct.Pull = GPIO_PULLUP;
  GPIO_InitStruct.Speed = GPIO_SPEED_FREQ_VERY_HIGH;
  GPIO_InitStruct.Alternate = GPIO_AF4_I2C3;
  HAL_GPIO_Init(GPIOH, &GPIO_InitStruct);

  /*Configure GPIO pins : ULPI_CLK_Pin ULPI_D0_Pin */
  GPIO_InitStruct.Pin = ULPI_CLK_Pin|ULPI_D0_Pin;
  GPIO_InitStruct.Mode = GPIO_MODE_AF_PP;
  GPIO_InitStruct.Pull = GPIO_NOPULL;
  GPIO_InitStruct.Speed = GPIO_SPEED_FREQ_VERY_HIGH;
  GPIO_InitStruct.Alternate = GPIO_AF10_OTG_HS;
  HAL_GPIO_Init(GPIOA, &GPIO_InitStruct);

}

/* USER CODE BEGIN 4 */

/*
###############################################
                    MAPPING
###############################################
*/

static void map_inputBuffer_to_frameBuffer(void){
    int row = 0; // from 0 to 7 (8)
    int part = 2; // from 0 to 2 (3)
    int counter = 0; // from 0 to 7 (8)
    int panel_row = 0; //from 0 to 3 (4)   4 10 24
    for(int j = 0; j<Y_SIZE;j++){
        row = j % ROWS;
        for(int i = 0; i<X_SIZE;i+=4){
            frameBuffer[row][panel_row*X_PANEL_NR*COLUMS_PER_PANEL+i*3+4*part+0]=inputBuffer[j*X_SIZE+i+0];
            frameBuffer[row][panel_row*X_PANEL_NR*COLUMS_PER_PANEL+i*3+4*part+1]=inputBuffer[j*X_SIZE+i+1];
            frameBuffer[row][panel_row*X_PANEL_NR*COLUMS_PER_PANEL+i*3+4*part+2]=inputBuffer[j*X_SIZE+i+2];
            frameBuffer[row][panel_row*X_PANEL_NR*COLUMS_PER_PANEL+i*3+4*part+3]=inputBuffer[j*X_SIZE+i+3];
        }
        counter++;
        if(counter % ROWS == 0){
            if(part != 0) part--;
            else part = 2;
        }
    if(counter % (ROWS*3) == 0) panel_row++;
    }
}

static void map_frameBuffer_to_outputBuffer(void){
    uint8_t reg = 0;
    for(int csf = 0; csf!=use_subframe_nr;csf++){
        for(int j = 0; j!=ROWS;j++){
            for(int i = 0; i!=SHIFTREGS;i+=1){
                reg = 0;
                if((frameBuffer[j][i*4+0] >> 4)   > csf) reg |=  1;
                if((frameBuffer[j][i*4+0] & 0x0f) > csf) reg |= (1 << 1);
                if((frameBuffer[j][i*4+1] >> 4)   > csf) reg |= (1 << 2);
                if((frameBuffer[j][i*4+1] & 0x0f) > csf) reg |= (1 << 3);
                if((frameBuffer[j][i*4+2] >> 4)   > csf) reg |= (1 << 4);
                if((frameBuffer[j][i*4+2] & 0x0f) > csf) reg |= (1 << 5);
                if((frameBuffer[j][i*4+3] >> 4)   > csf) reg |= (1 << 6);
                if((frameBuffer[j][i*4+3] & 0x0f) > csf) reg |= (1 << 7);
                if(current_buffer == 0) outputBuffer_0[csf*ROWS*SHIFTREGS + j*SHIFTREGS + SHIFTREGS-i-1] = reg;
                else if(current_buffer == 1) outputBuffer_1[csf*ROWS*SHIFTREGS + j*SHIFTREGS + SHIFTREGS-i-1] = reg;
            }
        }
    }
}

/*
###############################################
                  TEST PATTERN
###############################################
*/

static void test_Pattern_outputBuffer(void){
    for(int csf = 0; csf<SUBFRAMES;csf++){
        for(int j = 0; j<ROWS;j++){
            for(int i = 0; i<SHIFTREGS;i+=6){
                outputBuffer_0[csf*ROWS*SHIFTREGS + j*SHIFTREGS + i]   = 2;
                outputBuffer_0[csf*ROWS*SHIFTREGS + j*SHIFTREGS + i+1] = 2;
                outputBuffer_0[csf*ROWS*SHIFTREGS + j*SHIFTREGS + i+2] = 2;
                outputBuffer_0[csf*ROWS*SHIFTREGS + j*SHIFTREGS + i+3] = 2;
                outputBuffer_0[csf*ROWS*SHIFTREGS + j*SHIFTREGS + i+4] = 2;
                outputBuffer_0[csf*ROWS*SHIFTREGS + j*SHIFTREGS + i+5] = 2;
            }
        }
    }
}

static void test_Pattern_frameBuffer(void){
    for(int j = 0; j<ROWS;j++){
        for(int i = 0; i<COLUMS;i+=8){
            frameBuffer[j][i]   = 0x77;
            frameBuffer[j][i+1] = 0x66;
            frameBuffer[j][i+2] = 0x55;
            frameBuffer[j][i+3] = 0x44;
            frameBuffer[j][i+4] = 0x33;
            frameBuffer[j][i+5] = 0x22;
            frameBuffer[j][i+6] = 0x11;
            frameBuffer[j][i+7] = 0x00;
        }
    }
}

static void test_Pattern_inputBuffer(void){
  for(int j = 0; j<Y_SIZE;j++){
    for(int i = 0; i<X_SIZE;i+=8){
        inputBuffer[j*X_SIZE+i]   = 0x50;
        inputBuffer[j*X_SIZE+i+1] = 0x00;
        inputBuffer[j*X_SIZE+i+2] = 0x00;
        inputBuffer[j*X_SIZE+i+3] = 0x00;
        inputBuffer[j*X_SIZE+i+4] = 0x00;
        inputBuffer[j*X_SIZE+i+5] = 0x00;
        inputBuffer[j*X_SIZE+i+6] = 0x00;
        inputBuffer[j*X_SIZE+i+7] = 0x00;
    }
  }
}

/*
###############################################
                      SPI
###############################################
*/

void HAL_SPI_TxCpltCallback(SPI_HandleTypeDef * spi){
  //Transfer complete routien, called after DMA finnished sending data to spi

}

static void stop_display(void){
    stop_dmas = 1;
    new_input_frame = 0;
    new_output_frame = 0;
    reset();
}

static void start_display(void){
    stop_dmas = 0;
}

static void reset(void){
  currentRow = 0;
  currentPanelRow = 0;
  currentSubframe = 0;
  current_buffer = 0;
  HAL_GPIO_WritePin(latch_GPIO_Port,latch_Pin,0);
  HAL_GPIO_WritePin(row0_GPIO_Port,row0_Pin,0);
  HAL_GPIO_WritePin(row1_GPIO_Port,row1_Pin,0);
  HAL_GPIO_WritePin(row2_GPIO_Port,row2_Pin,0);
  HAL_GPIO_WritePin(row3_GPIO_Port,row3_Pin,0);
  HAL_GPIO_WritePin(row4_GPIO_Port,row4_Pin,0);
  HAL_GPIO_WritePin(row5_GPIO_Port,row5_Pin,0);
  HAL_GPIO_WritePin(row6_GPIO_Port,row6_Pin,0);
  HAL_GPIO_WritePin(row7_GPIO_Port,row7_Pin,0);
  memset(inputBuffer, 0, sizeof(inputBuffer));
  memset(frameBuffer, 0, sizeof(frameBuffer));
  memset(outputBuffer_0, 0, sizeof(outputBuffer_0));
  memset(outputBuffer_1, 0, sizeof(outputBuffer_1));
}

/*
###############################################
                       TCP
###############################################
*/

static uint8_t tcp_StateMachiene(char d){
   switch(tcp_state){

   case STATE_NONE:
      if(d=='s') tcp_state = STATE_S;
      else if(d=='d') tcp_state = STATE_D;
      else if(d=='m') tcp_state = STATE_M;
      else tcp_state = STATE_NONE;
      return NEXT;

   case STATE_S:
      if(d=='t') tcp_state = STATE_ST;
      else tcp_state = STATE_NONE;
      return NEXT;

   case STATE_ST:
      if(d=='a') tcp_state = STATE_STA;
      else tcp_state = STATE_NONE;
      return NEXT;

   case STATE_STA:
      if(d=='r') tcp_state = STATE_STAR;
      else tcp_state = STATE_NONE;
      return NEXT;

   case STATE_STAR:
      if(d=='t') tcp_state = STATE_START;
      else tcp_state = STATE_NONE;
      return NEXT;

   case STATE_START:
      tcp_state = STATE_HIGHBYTE;
      frame_len = d << 8;
      return NEXT;

   case STATE_HIGHBYTE:
      tcp_state = STATE_NONE;
      frame_len |=  d;
      if(frame_len <= sizeof(inputBuffer)) return GET_FRAME;

   case STATE_M:
      if(d=='o') tcp_state = STATE_MO;
      else tcp_state = STATE_NONE;
      return NEXT;

   case STATE_MO:
      if(d=='d') tcp_state = STATE_MOD;
      else tcp_state = STATE_NONE;
      return NEXT;

   case STATE_MOD:
      if(d=='e') tcp_state = STATE_MODE;
      else tcp_state = STATE_NONE;
      return NEXT;

   case STATE_MODE:
      if(d > 0 && d <= 255){
        max_fps = d;
        milli_max = 1000.0/(float)max_fps;
        if(USB_TCP_DEBUGG) memset(usb_data_out, 0, sizeof(usb_data_out));
        if(USB_TCP_DEBUGG) sprintf(usb_data_out, "Set framerate: %ld \r\n",max_fps);
        if(USB_TCP_DEBUGG) usb_send_data(usb_data_out,sizeof(usb_data_out),10000);
        tcp_state = STATE_MODE_1;
        return NEXT;
      }else{
        tcp_state = STATE_NONE;
        return NEXT;
      }

   case STATE_MODE_1:
      if(d > 0 && d <= 16){
        use_subframe_nr = d;
        if(USB_TCP_DEBUGG) memset(usb_data_out, 0, sizeof(usb_data_out));
        if(USB_TCP_DEBUGG) sprintf(usb_data_out, "Using %ld subframes.\r\n",use_subframe_nr);
        if(USB_TCP_DEBUGG) usb_send_data(usb_data_out,sizeof(usb_data_out),10000);
        tcp_state = STATE_MODE_2;
        return NEXT;
      }else{
        tcp_state = STATE_NONE;
        return NEXT;
      }

    case STATE_MODE_2:
      if(d == 0 || d==1){
        use_both_panels = d;
        if(USB_TCP_DEBUGG) memset(usb_data_out, 0, sizeof(usb_data_out));
        if(USB_TCP_DEBUGG) sprintf(usb_data_out, "Using both panels: %ld \r\n",use_both_panels);
        if(USB_TCP_DEBUGG) usb_send_data(usb_data_out,sizeof(usb_data_out),10000);
        tcp_state = STATE_NONE;
        return NEXT;
      }else{
        tcp_state = STATE_NONE;
        return NEXT;
      }

   case STATE_D:
      if(d=='m') tcp_state = STATE_DM;
      else tcp_state = STATE_NONE;
      return NEXT;

   case STATE_DM:
      if(d=='a') tcp_state = STATE_DMA;
      else tcp_state = STATE_NONE;
      return NEXT;

   case STATE_DMA:
      if(d=='0') stop_display();
      if(d=='1') start_display();
      if(USB_TCP_DEBUGG) memset(usb_data_out, 0, sizeof(usb_data_out));
      if(USB_TCP_DEBUGG && !stop_dmas) sprintf(usb_data_out, "Starting Display\r\n");
      if(USB_TCP_DEBUGG && stop_dmas) sprintf(usb_data_out, "Stopping Display\r\n");
      if(USB_TCP_DEBUGG) usb_send_data(usb_data_out,sizeof(usb_data_out),10000);
      tcp_state = STATE_NONE;
      return NEXT;

   default :
      if(USB_TCP_DEBUGG) memset(usb_data_out, 0, sizeof(usb_data_out));
      if(USB_TCP_DEBUGG) sprintf(usb_data_out, "Undefiend state. Current char: '%c'\r\n",d);
      if(USB_TCP_DEBUGG) usb_send_data(usb_data_out,sizeof(usb_data_out),10000);
      tcp_state = STATE_NONE;
      return NEXT;
  }
}

static void tcp_setup(void){
  err_t error;
  pcb_tcp = tcp_new();
  if(pcb_tcp == NULL){
    sprintf(tcp1_status,"no pcb_tcp");
    return;
  } else {
    sprintf(tcp1_status,"created pcb_tcp");
  }

  error = tcp_bind(pcb_tcp,IP4_ADDR_ANY,PORT_TCP_RECEIVE);
  if(error == ERR_USE){
    sprintf(tcp2_status, "Port %d already in use.", PORT_TCP_RECEIVE);
    return;
  } else if(error == ERR_VAL){
    sprintf(tcp2_status, "pcb_tcp not ready. Invalid Value.");
    return;
  } else if(error == ERR_OK){
    sprintf(tcp2_status, "pcb_tcp succesfully bound to port %d.",PORT_TCP_RECEIVE);
  }

  pcb_tcp = tcp_listen(pcb_tcp);
  if(pcb_tcp == NULL){
    sprintf(tcp3_status,"no pcb_tcp_listen");
    return;
  } else {
    sprintf(tcp3_status,"created pcb_tcp_listen");
  }

  tcp_accept(pcb_tcp,tcp_connection_accepted); 	// sets callback function for incoming connections

}

static err_t tcp_connection_accepted(void *arg, struct tcp_pcb *newpcb, err_t err){
    if(USB_TCP_DEBUGG) memset(usb_data_out, 0, sizeof(usb_data_out));
    if(USB_TCP_DEBUGG) sprintf(usb_data_out, "New connection.\r\n");
    if(USB_TCP_DEBUGG) usb_send_data(usb_data_out,sizeof(usb_data_out),10000);

    tcp_setprio(newpcb, TCP_PRIO_MAX);  // does this even do something?
    tcp_recv(newpcb, tcp_receive_callback); // sets receive callback function
    tcp_err(newpcb, NULL); //Don't care about error here
    tcp_poll(newpcb, tcp_poll_timeout, 1); // sets poll callback function and intervall (half-second wise)

    return ERR_OK;
}

static err_t tcp_receive_callback(void *arg, struct tcp_pcb *tpcb, struct pbuf *p, err_t err){
   if(p == NULL){ //check if remote host closed the connection.
        close_connection(tpcb, "Connection closed by remote host.");
        pbuf_free(p);
        current_position = 0;

   } else if (err == ERR_OK ){ // Process data
        uint32_t total_length = p->tot_len; // gets total length of pbuf
        while(1){
            uint32_t len = p->len;
            uint8_t *data = p->payload;
            uint32_t pos = 0; // next byte position to read
            tcp_connection_timeout_counter = 0;
            while(pos<len){ // feeds the statemachiene until tcp_recv_state == GET_FRAME
                if(tcp_recv_state == NEXT){
                    for(;pos < len;){
                        tcp_recv_state = tcp_StateMachiene((char)data[pos]);
                        pos++;
                        if(tcp_recv_state == GET_FRAME){
                            bytes_copied = 0;
                            if(USB_TCP_DEBUGG) memset(usb_data_out, 0, sizeof(usb_data_out));
                            if(USB_TCP_DEBUGG) sprintf(usb_data_out,\
                            "Receiving frame of length: %ld \r\nFirst 16 bytes: %x:%x:%x:%x:%x:%x:%x:%x \r\n",frame_len
                                ,data[pos],data[pos+1],data[pos+2],data[pos+3],data[pos+4],data[pos+5],data[pos+6],data[pos+7]);
                            if(USB_TCP_DEBUGG) usb_send_data(usb_data_out,sizeof(usb_data_out),10000);
                            break;
                        }
                    }
                }
                if(tcp_recv_state == GET_FRAME){ // copies bytes into input_buffer until frame_len bytes are copied
                    bytes_to_copy = len-pos;
                    if(bytes_to_copy+bytes_copied > frame_len) bytes_to_copy = frame_len-bytes_copied;
                    memcpy(&inputBuffer[bytes_copied],&data[pos],bytes_to_copy);
                    bytes_copied += bytes_to_copy;
                    pos += bytes_to_copy;
                    if(bytes_copied >= frame_len){ // frame fully recieved, start display, set new_input_frame flag and move frame to output_buffer
                        if(USB_TCP_DEBUGG) memset(usb_data_out, 0, sizeof(usb_data_out));
                        if(USB_TCP_DEBUGG) sprintf(usb_data_out, "New frame complete! Received %ld\r\n",bytes_copied);
                        if(USB_TCP_DEBUGG) usb_send_data(usb_data_out,sizeof(usb_data_out),10000);
                        tcp_recv_state = NEXT; // reset state
                        bytes_copied = 0;
                        bytes_to_copy = 0;
                        start_display();
                        while(!next_frame){} // next_frame gets set by a timer to keep the framerate
                        new_output_frame = 1;
                        dma_swiched = 0;
                        next_frame = 0; // reset
                        map_inputBuffer_to_frameBuffer(); // to frame buffer
                        map_frameBuffer_to_outputBuffer(); // to output buffer
                        if(USB_MAP_DEBUGG) memset(usb_data_out, 0, sizeof(usb_data_out));
                        if(USB_MAP_DEBUGG) sprintf(usb_data_out,
                            "Processed new frame. fps: %ld rps: %ld buffer: %ld \r\n",fps,rps,current_buffer);
                        if(USB_MAP_DEBUGG) usb_send_data(usb_data_out,sizeof(usb_data_out),10000);
                    }
                }
            }
            if (p->tot_len > p->len){
                if(USB_PBUF_DEBUGG) memset(usb_data_out, 0, sizeof(usb_data_out));
                if(USB_PBUF_DEBUGG) sprintf(usb_data_out, "Next Pbuf. tot_len: %ld, len: %ld \r\n",p->tot_len,p->len);
                if(USB_PBUF_DEBUGG) usb_send_data(usb_data_out,sizeof(usb_data_out),10000);
                p = p->next;
            }
            else{
                if(USB_PBUF_DEBUGG) memset(usb_data_out, 0, sizeof(usb_data_out));
                if(USB_PBUF_DEBUGG) sprintf(usb_data_out, "Pbuf empty.\r\n");
                if(USB_PBUF_DEBUGG) usb_send_data(usb_data_out,sizeof(usb_data_out),10000);
                break;
            }
        }
        tcp_recved(tpcb, total_length);
        pbuf_free(p);

    } else { // if a different error then ERR_OK appears, the connection will be closed.
        close_connection(tpcb, "Transfer aborted or oder unknown error.");
        pbuf_free(p);
        current_position = 0;
        new_input_frame = 0;
    }
    return ERR_OK;
}

static err_t tcp_poll_timeout(void *args,struct tcp_pcb *tpcb){ // poll for timeout
    tcp_connection_timeout_counter++;
    if(tcp_connection_timeout_counter < TCP_CONNECTION_TIMEOUT){

    } else {
        close_connection(tpcb,"Connection timeout.");
        tcp_connection_timeout_counter = 0;
    }
    return ERR_OK;
}

static void close_connection(struct tcp_pcb *pcb, char *reason){
      if(USB_TCP_DEBUGG) memset(usb_data_out, 0, sizeof(usb_data_out));
      if(USB_TCP_DEBUGG) sprintf(usb_data_out, "Connection was closed.\r\nReason: '%s' \r\n",reason);
      if(USB_TCP_DEBUGG) usb_send_data(usb_data_out,sizeof(usb_data_out),10000);

      //stop_display();
      tcp_recv_state = NEXT;

      // close the tcp connection
      tcp_connection_timeout_counter = 0;
      tcp_arg(pcb, NULL);
      tcp_sent(pcb, NULL);
      tcp_recv(pcb, NULL);
      tcp_close(pcb);
}

/*
###############################################
                     MISC
###############################################
*/

static void update_fps(void){
        fps = 1000.0/(HAL_GetTick()-t_fps);
        t_fps = HAL_GetTick();
}

static void update_rps(void){
        rps = 1000.0/(HAL_GetTick()-t_rps);
        t_rps = HAL_GetTick();
}

static void send_status(void){
    if(USB_NET_STATUS){
        my_ip.ip_hex = netif_ip4_addr(&gnetif)->addr;
        my_ip.d = (my_ip.ip_hex & 0xff000000) >> 24;
        my_ip.c = (my_ip.ip_hex & 0x00ff0000) >> 16;
        my_ip.b = (my_ip.ip_hex & 0x0000ff00) >> 8;
        my_ip.a = (my_ip.ip_hex & 0x000000ff) >> 0;

        memset(usb_data_out, 0, sizeof(usb_data_out));
        sprintf(usb_data_out,\
"##### Status Message #####\r\n \
    IP Addr: %d.%d.%d.%d\r\n \
    netif_is_up: %d\r\n \
    netif_is_link_up: %d\r\n \
    %s\r\n \
    %s\r\n \
    %s\r\n \
    fps: %ld\r\n \
    rps: %ld\r\n \
#######################\r\n"
        ,my_ip.a,my_ip.b,my_ip.c,my_ip.d,netif_is_up(&gnetif),netif_is_link_up(&gnetif),tcp1_status,tcp2_status,tcp3_status,fps,rps);
        usb_send_data(usb_data_out,sizeof(usb_data_out),50000);
    }
}

/* USER CODE END 4 */

void HAL_TIM_PeriodElapsedCallback(TIM_HandleTypeDef *htim)
{
  /* USER CODE BEGIN Callback 0 */
  if (htim->Instance == TIM6) {
    milli_counter++;
    if(milli_counter >= milli_max){
        milli_counter = 0;
        next_frame = 1;

    }
  }
  /* USER CODE END Callback 0 */
  if (htim->Instance == TIM6) {
    HAL_IncTick();
  }
  /* USER CODE BEGIN Callback 1 */
  if(htim->Instance == TIM9){
  //tim9_counter++;
  dma_spi_done = 1;
  if(!stop_dmas){
        dma_timeout = 0;
        HAL_SPI_DMAStop(&hspi2);
        HAL_SPI_DMAStop(&hspi5);

        if(currentPanelRow == 0){

            HAL_GPIO_WritePin(row0_GPIO_Port,row0_Pin,0); // turn all rows off
            HAL_GPIO_WritePin(row1_GPIO_Port,row1_Pin,0);
            HAL_GPIO_WritePin(row2_GPIO_Port,row2_Pin,0);
            HAL_GPIO_WritePin(row3_GPIO_Port,row3_Pin,0);
            HAL_GPIO_WritePin(row4_GPIO_Port,row4_Pin,0);
            HAL_GPIO_WritePin(row5_GPIO_Port,row5_Pin,0);
            HAL_GPIO_WritePin(row6_GPIO_Port,row6_Pin,0);
            HAL_GPIO_WritePin(row7_GPIO_Port,row7_Pin,0);

            //for(volatile int i=0;i<LATCH_DELAY;i++){} // NOPs to wait after rows are turned off. Prevents ghosting between frames.

            // Latch the previosly sent data to shift-register output
            HAL_GPIO_WritePin(bank_sel_GPIO_Port,bank_sel_Pin,!currentPanelRow); // Latch for both bank_sel states
            HAL_GPIO_WritePin(latch_GPIO_Port,latch_Pin,1);
            HAL_GPIO_WritePin(bank_sel_GPIO_Port,bank_sel_Pin,currentPanelRow);
            HAL_GPIO_WritePin(latch_GPIO_Port,latch_Pin,0);

            HAL_GPIO_WritePin(row0_GPIO_Port,row0_Pin,currentRow==0);
            HAL_GPIO_WritePin(row1_GPIO_Port,row1_Pin,currentRow==1); // turn on respective row
            HAL_GPIO_WritePin(row2_GPIO_Port,row2_Pin,currentRow==2);
            HAL_GPIO_WritePin(row3_GPIO_Port,row3_Pin,currentRow==3);
            HAL_GPIO_WritePin(row4_GPIO_Port,row4_Pin,currentRow==4);
            HAL_GPIO_WritePin(row5_GPIO_Port,row5_Pin,currentRow==5);
            HAL_GPIO_WritePin(row6_GPIO_Port,row6_Pin,currentRow==6);
            HAL_GPIO_WritePin(row7_GPIO_Port,row7_Pin,currentRow==7);
            currentRow++;
            if(currentRow >= ROWS){
                currentRow = 0;
                currentSubframe++;
                if(currentSubframe >= use_subframe_nr){
                    currentSubframe = 0;
                    update_rps();
                    // if the current subframe is 0, the last frame has been completly displayed. Check if there is a new frame.
                    // otherwise reuse the old one.
                    if(new_output_frame){
                        current_buffer = (current_buffer==0?1:0);
                        update_fps();
                        new_output_frame = 0;
                        dma_swiched = 1;
                    }
                }
            }
        }

        dma_spi_done = 0;
        HAL_GPIO_WritePin(bank_sel_GPIO_Port,bank_sel_Pin,currentPanelRow);
        if(current_buffer==1){
           spi2_err = HAL_SPI_Transmit_DMA(&hspi2,&outputBuffer_0[currentSubframe*ROWS*SHIFTREGS+currentRow*SHIFTREGS+currentPanelRow*120],60);
           spi5_err = HAL_SPI_Transmit_DMA(&hspi5,&outputBuffer_0[currentSubframe*ROWS*SHIFTREGS+currentRow*SHIFTREGS+currentPanelRow*120+60],60);
        }else if(current_buffer==0){
           spi2_err = HAL_SPI_Transmit_DMA(&hspi2,&outputBuffer_1[currentSubframe*ROWS*SHIFTREGS+currentRow*SHIFTREGS+currentPanelRow*120],60);
           spi5_err = HAL_SPI_Transmit_DMA(&hspi5,&outputBuffer_1[currentSubframe*ROWS*SHIFTREGS+currentRow*SHIFTREGS+currentPanelRow*120+60],60);
        }
        if(use_both_panels){
            currentPanelRow++;
            if(currentPanelRow >= 2) currentPanelRow = 0;
        }
        else currentPanelRow = 0;

        if(spi2_err != HAL_OK || spi5_err != HAL_OK){
            spi2_error = spi2_err;
            spi5_error = spi5_err;
        }
    }

   }

  /* USER CODE END Callback 1 */
}

void _Error_Handler(char *file, int line)
{
  /* USER CODE BEGIN Error_Handler_Debug */
  /* User can add his own implementation to report the HAL error return state */
  while(1)
  {
    HAL_GPIO_WritePin(row0_GPIO_Port,row0_Pin,0); // turn all rows off
    HAL_GPIO_WritePin(row1_GPIO_Port,row1_Pin,0);
    HAL_GPIO_WritePin(row2_GPIO_Port,row2_Pin,0);
    HAL_GPIO_WritePin(row3_GPIO_Port,row3_Pin,0);
    HAL_GPIO_WritePin(row4_GPIO_Port,row4_Pin,0);
    HAL_GPIO_WritePin(row5_GPIO_Port,row5_Pin,0);
    HAL_GPIO_WritePin(row6_GPIO_Port,row6_Pin,0);
    HAL_GPIO_WritePin(row7_GPIO_Port,row7_Pin,0);
    memset(usb_data_out, 0, sizeof(usb_data_out));
    sprintf(usb_data_out, "#### CRITICAL ERROR!! ####");
    usb_send_data(usb_data_out,sizeof(usb_data_out),10000);
    HAL_Delay(500);
  }
  /* USER CODE END Error_Handler_Debug */
}

/************************ (C) COPYRIGHT STMicroelectronics *****END OF FILE****/
